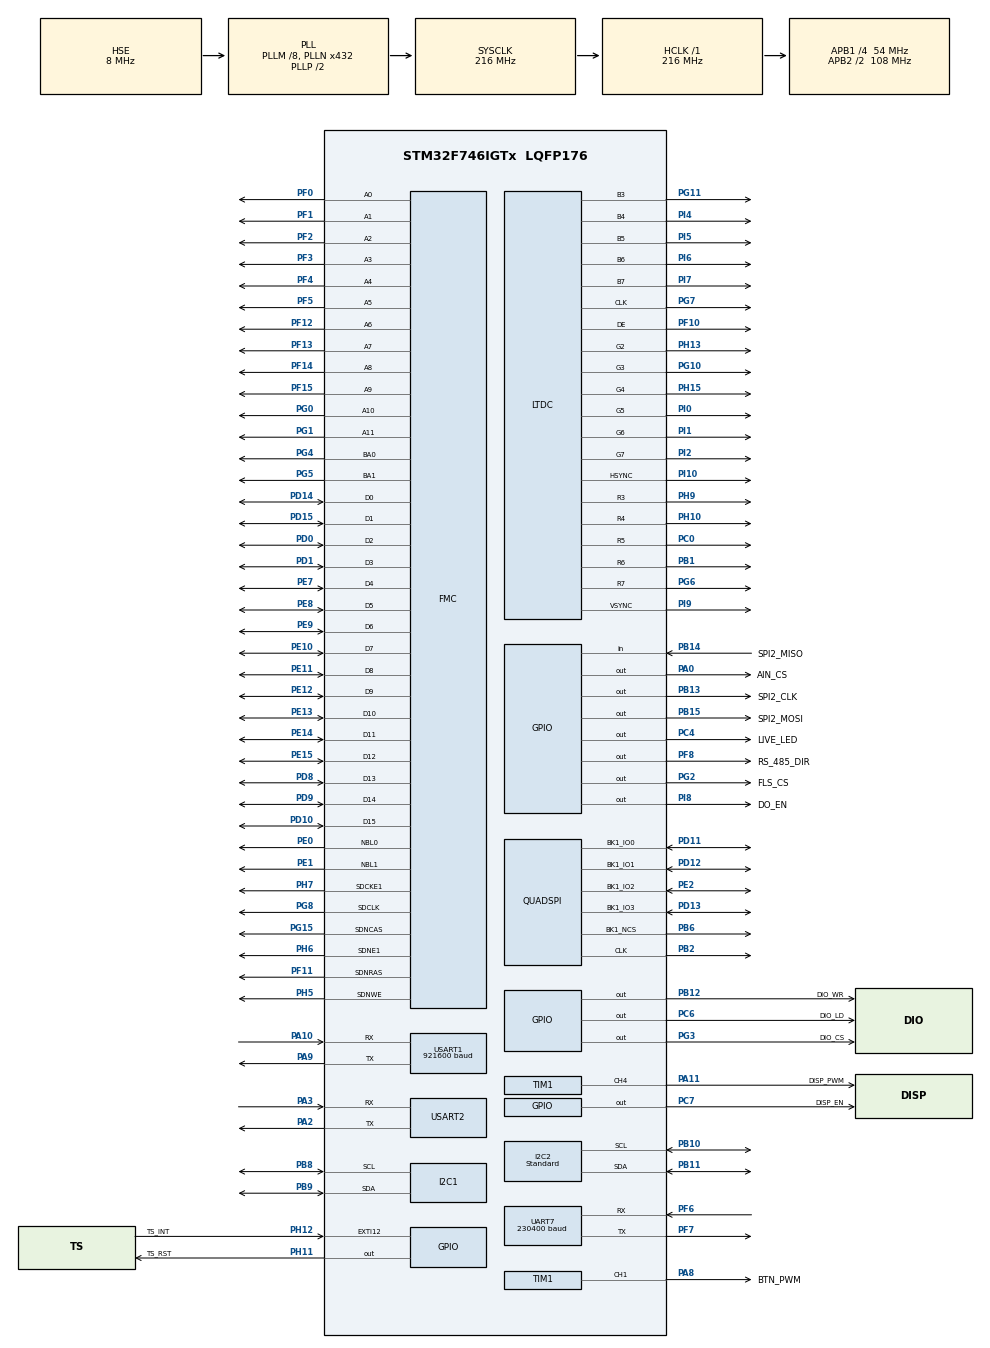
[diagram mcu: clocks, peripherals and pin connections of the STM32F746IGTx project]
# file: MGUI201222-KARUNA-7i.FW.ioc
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CORTEX_M7.ART_ACCLERATOR_ENABLE=1
CORTEX_M7.AccessPermission-Cortex_Memory_Protection_Unit_Region0_Settings=MPU_REGION_FULL_ACCESS
CORTEX_M7.AccessPermission-Cortex_Memory_Protection_Unit_Region1_Settings=MPU_REGION_FULL_ACCESS
CORTEX_M7.BaseAddress-Cortex_Memory_Protection_Unit_Region0_Settings=0x90000000
CORTEX_M7.BaseAddress-Cortex_Memory_Protection_Unit_Region1_Settings=0xD0000000
CORTEX_M7.CPU_DCache=Enabled
CORTEX_M7.CPU_ICache=Enabled
CORTEX_M7.Enable-Cortex_Memory_Protection_Unit_Region0_Settings=MPU_REGION_ENABLE
CORTEX_M7.Enable-Cortex_Memory_Protection_Unit_Region1_Settings=MPU_REGION_ENABLE
CORTEX_M7.IsCacheable-Cortex_Memory_Protection_Unit_Region0_Settings=MPU_ACCESS_NOT_CACHEABLE
CORTEX_M7.IsCacheable-Cortex_Memory_Protection_Unit_Region1_Settings=MPU_ACCESS_CACHEABLE
CORTEX_M7.MPU_Control=__NULL
CORTEX_M7.PREFETCH_ENABLE=1
CORTEX_M7.Size-Cortex_Memory_Protection_Unit_Region0_Settings=MPU_REGION_SIZE_256MB
CORTEX_M7.Size-Cortex_Memory_Protection_Unit_Region1_Settings=MPU_REGION_SIZE_256MB
CORTEX_M7.SubRegionDisable-Cortex_Memory_Protection_Unit_Region0_Settings=0x0
DMA2D.ColorMode=DMA2D_OUTPUT_RGB565
Dma.Request0=USART1_RX
Dma.Request1=UART7_RX
Dma.UART7_RX.1.Direction=DMA_PERIPH_TO_MEMORY
Dma.UART7_RX.1.FIFOMode=DMA_FIFOMODE_DISABLE
Dma.UART7_RX.1.Instance=DMA1_Stream3
Dma.UART7_RX.1.MemDataAlignment=DMA_MDATAALIGN_BYTE
Dma.UART7_RX.1.MemInc=DMA_MINC_ENABLE
Dma.UART7_RX.1.Mode=DMA_NORMAL
Dma.UART7_RX.1.PeriphDataAlignment=DMA_PDATAALIGN_BYTE
Dma.UART7_RX.1.PeriphInc=DMA_PINC_DISABLE
Dma.UART7_RX.1.Priority=DMA_PRIORITY_MEDIUM
Dma.USART1_RX.0.Direction=DMA_PERIPH_TO_MEMORY
Dma.USART1_RX.0.FIFOMode=DMA_FIFOMODE_DISABLE
Dma.USART1_RX.0.Instance=DMA2_Stream2
Dma.USART1_RX.0.MemDataAlignment=DMA_MDATAALIGN_BYTE
Dma.USART1_RX.0.MemInc=DMA_MINC_ENABLE
Dma.USART1_RX.0.Mode=DMA_NORMAL
Dma.USART1_RX.0.PeriphDataAlignment=DMA_PDATAALIGN_BYTE
Dma.USART1_RX.0.PeriphInc=DMA_PINC_DISABLE
Dma.USART1_RX.0.Priority=DMA_PRIORITY_MEDIUM
FMC.CASLatency1=FMC_SDRAM_CAS_LATENCY_3
FMC.ExitSelfRefreshDelay1=7
FMC.LoadToActiveDelay1=2
FMC.RCDDelay1=2
FMC.RPDelay1=2
FMC.RPDelay2=2
FMC.ReadBurst1=FMC_SDRAM_RBURST_ENABLE
FMC.ReadBurst2=FMC_SDRAM_RBURST_ENABLE
FMC.RowCycleDelay1=7
FMC.RowCycleDelay2=7
FMC.SDClockPeriod1=FMC_SDRAM_CLOCK_PERIOD_2
FMC.SDClockPeriod2=FMC_SDRAM_CLOCK_PERIOD_2
FMC.SelfRefreshTime1=4
FMC.WriteRecoveryTime1=3
FREERTOS.MEMORY_ALLOCATION=0
FREERTOS.Queues01=USBUartRxQueue,16,80,1,Dynamic,NULL,NULL
FREERTOS.Tasks01=defaultTask,24,8192,StartDefaultTask,Default,NULL,Dynamic,NULL,NULL;UsbRx_Task,24,8192,UsbRxTask,Default,NULL,Dynamic,NULL,NULL;LiveLed_Task,24,128,LiveLedOsTask,Default,NULL,Dynamic,NULL,NULL;RS485Rx_Task,24,8192,RS485RxTask,Default,NULL,Dynamic,NULL,NULL;RS485Tx_Task,24,128,RS485TxTask,Default,NULL,Dynamic,NULL,NULL;Peri_Task,24,128,PeriTask,Default,NULL,Dynamic,NULL,NULL
FREERTOS.configGENERATE_RUN_TIME_STATS=1
FREERTOS.configTOTAL_HEAP_SIZE=128000
FREERTOS.configUSE_APPLICATION_TASK_TAG=1
FREERTOS.configUSE_COUNTING_SEMAPHORES=1
FREERTOS.configUSE_IDLE_HOOK=1
FREERTOS.configUSE_NEWLIB_REENTRANT=1
FREERTOS.configUSE_RECURSIVE_MUTEXES=1
I2C1.Timing=0x20404768
I2C2.I2C_Speed_Mode=I2C_Standard
I2C2.Speed=40
I2C2.Timing=0x2040BEFF
LTDC.ActiveH=600
LTDC.ActiveW=1024
LTDC.Alpha_L0=0xFF
LTDC.Alpha_L1=0
LTDC.BlendingFactor1_L0=LTDC_BLENDING_FACTOR1_CA
LTDC.BlendingFactor1_L1=LTDC_BLENDING_FACTOR1_PAxCA
LTDC.BlendingFactor2_L0=LTDC_BLENDING_FACTOR2_CA
LTDC.BlendingFactor2_L1=LTDC_BLENDING_FACTOR2_PAxCA
LTDC.FBStartAdress_L0=0xD0000000
LTDC.FBStartAdress_L1=0xD0200000
LTDC.HBP=140
LTDC.HFP=160
LTDC.HSync=20
LTDC.ImageHeight_L0=600
LTDC.ImageHeight_L1=600
LTDC.ImageWidth_L0=1024
LTDC.ImageWidth_L1=1024
LTDC.Layers=0
LTDC.PixelFormat_L0=LTDC_PIXEL_FORMAT_RGB565
LTDC.VBP=20
LTDC.VFP=12
LTDC.VSync=3
LTDC.WindowX1_L0=1024
LTDC.WindowX1_L1=1024
LTDC.WindowY1_L0=600
LTDC.WindowY1_L1=600
Mcu.Family=STM32F7
Mcu.Name=STM32F746IGTx
Mcu.Package=LQFP176
NVIC.DMA1_Stream3_IRQn=true\:5\:0\:false\:false\:true\:true\:false\:true\:true
NVIC.DMA2D_IRQn=true\:5\:0\:true\:false\:true\:false\:true\:true\:true
NVIC.DMA2_Stream2_IRQn=true\:5\:0\:false\:false\:true\:true\:false\:true\:true
NVIC.EXTI15_10_IRQn=true\:5\:0\:false\:false\:true\:true\:true\:true\:true
NVIC.LTDC_ER_IRQn=true\:5\:0\:false\:false\:true\:false\:true\:true\:true
NVIC.LTDC_IRQn=true\:5\:0\:true\:false\:true\:false\:true\:true\:true
NVIC.PriorityGroup=NVIC_PRIORITYGROUP_4
NVIC.TIM6_DAC_IRQn=true\:15\:0\:false\:false\:true\:false\:false\:true\:true
NVIC.TimeBase=TIM6_DAC_IRQn
NVIC.TimeBaseIP=TIM6
PA0/WKUP.GPIO_Label=AIN_CS
PA0/WKUP.GPIO_PuPd=GPIO_PULLUP
PA0/WKUP.PinState=GPIO_PIN_SET
PA0/WKUP.Signal=GPIO_Output
PA10.Mode=Asynchronous
PA10.Signal=USART1_RX
PA11.GPIO_Label=DISP_PWM
PA11.Signal=S_TIM1_CH4
PA13.Mode=Trace_Asynchronous_SW
PA13.Signal=SYS_JTMS-SWDIO
PA14.Mode=Trace_Asynchronous_SW
PA14.Signal=SYS_JTCK-SWCLK
PA2.Mode=Asynchronous
PA2.Signal=USART2_TX
PA3.Mode=Asynchronous
PA3.Signal=USART2_RX
PA8.GPIO_Label=BTN_PWM
PA8.Signal=S_TIM1_CH1
PA9.Mode=Asynchronous
PA9.Signal=USART1_TX
PB1.GPIO_Mode=GPIO_MODE_AF_PP
PB1.GPIO_PuPd=GPIO_NOPULL
PB1.GPIO_Speed=GPIO_SPEED_FREQ_VERY_HIGH
PB1.Mode=RGB565
PB1.Signal=LTDC_R6
PB10.GPIO_Pu=GPIO_PULLUP
PB10.Mode=I2C
PB10.Signal=I2C2_SCL
PB11.GPIO_Pu=GPIO_PULLUP
PB11.Mode=I2C
PB11.Signal=I2C2_SDA
PB12.GPIO_Label=DIO_WR
PB12.Signal=GPIO_Output
PB13.GPIO_Label=SPI2_CLK
PB13.Signal=GPIO_Output
PB14.GPIO_Label=SPI2_MISO
PB14.Signal=GPIO_Input
PB15.GPIO_Label=SPI2_MOSI
PB15.Signal=GPIO_Output
PB2.Mode=Single Bank 1
PB2.Signal=QUADSPI_CLK
PB3.Mode=Trace_Asynchronous_SW
PB3.Signal=SYS_JTDO-SWO
PB6.Mode=Single Bank 1
PB6.Signal=QUADSPI_BK1_NCS
PB8.Mode=I2C
PB8.Signal=I2C1_SCL
PB9.Mode=I2C
PB9.Signal=I2C1_SDA
PC0.GPIO_Mode=GPIO_MODE_AF_PP
PC0.GPIO_PuPd=GPIO_NOPULL
PC0.GPIO_Speed=GPIO_SPEED_FREQ_VERY_HIGH
PC0.Mode=RGB565
PC0.Signal=LTDC_R5
PC14/OSC32_IN.Mode=LSE-External-Oscillator
PC14/OSC32_IN.Signal=RCC_OSC32_IN
PC15/OSC32_OUT.Mode=LSE-External-Oscillator
PC15/OSC32_OUT.Signal=RCC_OSC32_OUT
PC4.GPIO_Label=LIVE_LED
PC4.Signal=GPIO_Output
PC6.GPIO_Label=DIO_LD
PC6.Signal=GPIO_Output
PC7.GPIO_Label=DISP_EN
PC7.GPIO_PuPd=GPIO_PULLDOWN
PC7.PinState=GPIO_PIN_RESET
PC7.Signal=GPIO_Output
PD0.Signal=FMC_D2_DA2
PD1.Signal=FMC_D3_DA3
PD10.Signal=FMC_D15_DA15
PD11.Mode=Single Bank 1
PD11.Signal=QUADSPI_BK1_IO0
PD12.Mode=Single Bank 1
PD12.Signal=QUADSPI_BK1_IO1
PD13.Mode=Single Bank 1
PD13.Signal=QUADSPI_BK1_IO3
PD14.Signal=FMC_D0_DA0
PD15.Signal=FMC_D1_DA1
PD6.GPIO_Mode=GPIO_MODE_AF_PP
PD6.GPIO_PuPd=GPIO_NOPULL
PD6.GPIO_Speed=GPIO_SPEED_FREQ_VERY_HIGH
PD6.Signal=LTDC_B2
PD8.Signal=FMC_D13_DA13
PD9.Signal=FMC_D14_DA14
PE0.Signal=FMC_NBL0
PE1.Signal=FMC_NBL1
PE10.Signal=FMC_D7_DA7
PE11.Signal=FMC_D8_DA8
PE12.Signal=FMC_D9_DA9
PE13.Signal=FMC_D10_DA10
PE14.Signal=FMC_D11_DA11
PE15.Signal=FMC_D12_DA12
PE2.Mode=Single Bank 1
PE2.Signal=QUADSPI_BK1_IO2
PE4.GPIO_Mode=GPIO_MODE_AF_PP
PE4.GPIO_PuPd=GPIO_NOPULL
PE4.GPIO_Speed=GPIO_SPEED_FREQ_VERY_HIGH
PE4.Signal=LTDC_B0
PE5.GPIO_Mode=GPIO_MODE_AF_PP
PE5.GPIO_PuPd=GPIO_NOPULL
PE5.GPIO_Speed=GPIO_SPEED_FREQ_VERY_HIGH
PE5.Signal=LTDC_G0
PE6.GPIO_Mode=GPIO_MODE_AF_PP
PE6.GPIO_PuPd=GPIO_NOPULL
PE6.GPIO_Speed=GPIO_SPEED_FREQ_VERY_HIGH
PE6.Signal=LTDC_G1
PE7.Signal=FMC_D4_DA4
PE8.Signal=FMC_D5_DA5
PE9.Signal=FMC_D6_DA6
PF0.Signal=FMC_A0
PF1.Signal=FMC_A1
PF10.GPIO_Mode=GPIO_MODE_AF_PP
PF10.GPIO_PuPd=GPIO_NOPULL
PF10.GPIO_Speed=GPIO_SPEED_FREQ_VERY_HIGH
PF10.Mode=RGB565
PF10.Signal=LTDC_DE
PF11.Signal=FMC_SDNRAS
PF12.Signal=FMC_A6
PF13.Signal=FMC_A7
PF14.Signal=FMC_A8
PF15.Signal=FMC_A9
PF2.Signal=FMC_A2
PF3.Signal=FMC_A3
PF4.Signal=FMC_A4
PF5.Signal=FMC_A5
PF6.Mode=Asynchronous
PF6.Signal=UART7_RX
PF7.Mode=Asynchronous
PF7.Signal=UART7_TX
PF8.GPIO_Label=RS_485_DIR
PF8.Signal=GPIO_Output
PG0.Signal=FMC_A10
PG1.Signal=FMC_A11
PG10.GPIO_Mode=GPIO_MODE_AF_PP
PG10.GPIO_PuPd=GPIO_NOPULL
PG10.GPIO_Speed=GPIO_SPEED_FREQ_VERY_HIGH
PG10.Mode=RGB565
PG10.Signal=LTDC_G3
PG11.GPIO_Mode=GPIO_MODE_AF_PP
PG11.GPIO_PuPd=GPIO_NOPULL
PG11.GPIO_Speed=GPIO_SPEED_FREQ_VERY_HIGH
PG11.Mode=RGB565
PG11.Signal=LTDC_B3
PG12.GPIO_Mode=GPIO_MODE_AF_PP
PG12.GPIO_PuPd=GPIO_NOPULL
PG12.GPIO_Speed=GPIO_SPEED_FREQ_VERY_HIGH
PG12.Signal=LTDC_B1
PG15.Signal=FMC_SDNCAS
PG2.GPIO_Label=FLS_CS
PG2.GPIO_ModeDefaultOutputPP=GPIO_MODE_OUTPUT_PP
PG2.GPIO_PuPd=GPIO_PULLUP
PG2.GPIO_Speed=GPIO_SPEED_FREQ_LOW
PG2.PinState=GPIO_PIN_SET
PG2.Signal=GPIO_Output
PG3.GPIO_Label=DIO_CS
PG3.GPIO_ModeDefaultOutputPP=GPIO_MODE_OUTPUT_PP
PG3.GPIO_PuPd=GPIO_PULLUP
PG3.GPIO_Speed=GPIO_SPEED_FREQ_LOW
PG3.PinState=GPIO_PIN_SET
PG3.Signal=GPIO_Output
PG4.Signal=FMC_A14_BA0
PG5.Signal=FMC_A15_BA1
PG6.GPIO_Mode=GPIO_MODE_AF_PP
PG6.GPIO_PuPd=GPIO_NOPULL
PG6.GPIO_Speed=GPIO_SPEED_FREQ_VERY_HIGH
PG6.Mode=RGB565
PG6.Signal=LTDC_R7
PG7.GPIO_Mode=GPIO_MODE_AF_PP
PG7.GPIO_PuPd=GPIO_NOPULL
PG7.GPIO_Speed=GPIO_SPEED_FREQ_VERY_HIGH
PG7.Mode=RGB565
PG7.Signal=LTDC_CLK
PG8.Signal=FMC_SDCLK
PH0/OSC_IN.Mode=HSE-External-Oscillator
PH0/OSC_IN.Signal=RCC_OSC_IN
PH1/OSC_OUT.Mode=HSE-External-Oscillator
PH1/OSC_OUT.Signal=RCC_OSC_OUT
PH10.GPIO_Mode=GPIO_MODE_AF_PP
PH10.GPIO_PuPd=GPIO_NOPULL
PH10.GPIO_Speed=GPIO_SPEED_FREQ_VERY_HIGH
PH10.Mode=RGB565
PH10.Signal=LTDC_R4
PH11.GPIO_Label=TS_RST
PH11.Signal=GPIO_Output
PH12.GPIO_Label=TS_INT
PH12.GPIO_ModeDefaultEXTI=GPIO_MODE_IT_FALLING
PH12.GPIO_PuPd=GPIO_PULLUP
PH12.Signal=GPXTI12
PH13.GPIO_Mode=GPIO_MODE_AF_PP
PH13.GPIO_PuPd=GPIO_NOPULL
PH13.GPIO_Speed=GPIO_SPEED_FREQ_VERY_HIGH
PH13.Mode=RGB565
PH13.Signal=LTDC_G2
PH15.GPIO_Mode=GPIO_MODE_AF_PP
PH15.GPIO_PuPd=GPIO_NOPULL
PH15.GPIO_Speed=GPIO_SPEED_FREQ_VERY_HIGH
PH15.Mode=RGB565
PH15.Signal=LTDC_G4
PH2.GPIO_Mode=GPIO_MODE_AF_PP
PH2.GPIO_PuPd=GPIO_NOPULL
PH2.GPIO_Speed=GPIO_SPEED_FREQ_VERY_HIGH
PH2.Signal=LTDC_R0
PH3.GPIO_Mode=GPIO_MODE_AF_PP
PH3.GPIO_PuPd=GPIO_NOPULL
PH3.GPIO_Speed=GPIO_SPEED_FREQ_VERY_HIGH
PH3.Signal=LTDC_R1
PH5.Signal=FMC_SDNWE
PH6.Mode=SdramChipSelect2_1
PH6.Signal=FMC_SDNE1
PH7.Mode=SdramChipSelect2_1
PH7.Signal=FMC_SDCKE1
PH8.GPIO_Mode=GPIO_MODE_AF_PP
PH8.GPIO_PuPd=GPIO_NOPULL
PH8.GPIO_Speed=GPIO_SPEED_FREQ_VERY_HIGH
PH8.Signal=LTDC_R2
PH9.GPIO_Mode=GPIO_MODE_AF_PP
PH9.GPIO_PuPd=GPIO_NOPULL
PH9.GPIO_Speed=GPIO_SPEED_FREQ_VERY_HIGH
PH9.Mode=RGB565
PH9.Signal=LTDC_R3
PI0.GPIO_Mode=GPIO_MODE_AF_PP
PI0.GPIO_PuPd=GPIO_NOPULL
PI0.GPIO_Speed=GPIO_SPEED_FREQ_VERY_HIGH
PI0.Mode=RGB565
PI0.Signal=LTDC_G5
PI1.GPIO_Mode=GPIO_MODE_AF_PP
PI1.GPIO_PuPd=GPIO_NOPULL
PI1.GPIO_Speed=GPIO_SPEED_FREQ_VERY_HIGH
PI1.Mode=RGB565
PI1.Signal=LTDC_G6
PI10.GPIO_Mode=GPIO_MODE_AF_PP
PI10.GPIO_PuPd=GPIO_NOPULL
PI10.GPIO_Speed=GPIO_SPEED_FREQ_VERY_HIGH
PI10.Mode=RGB565
PI10.Signal=LTDC_HSYNC
PI2.GPIO_Mode=GPIO_MODE_AF_PP
PI2.GPIO_PuPd=GPIO_NOPULL
PI2.GPIO_Speed=GPIO_SPEED_FREQ_VERY_HIGH
PI2.Mode=RGB565
PI2.Signal=LTDC_G7
PI4.GPIO_Mode=GPIO_MODE_AF_PP
PI4.GPIO_PuPd=GPIO_NOPULL
PI4.GPIO_Speed=GPIO_SPEED_FREQ_VERY_HIGH
PI4.Mode=RGB565
PI4.Signal=LTDC_B4
PI5.GPIO_Mode=GPIO_MODE_AF_PP
PI5.GPIO_PuPd=GPIO_NOPULL
PI5.GPIO_Speed=GPIO_SPEED_FREQ_VERY_HIGH
PI5.Mode=RGB565
PI5.Signal=LTDC_B5
PI6.GPIO_Mode=GPIO_MODE_AF_PP
PI6.GPIO_PuPd=GPIO_NOPULL
PI6.GPIO_Speed=GPIO_SPEED_FREQ_VERY_HIGH
PI6.Mode=RGB565
PI6.Signal=LTDC_B6
PI7.GPIO_Mode=GPIO_MODE_AF_PP
PI7.GPIO_PuPd=GPIO_NOPULL
PI7.GPIO_Speed=GPIO_SPEED_FREQ_VERY_HIGH
PI7.Mode=RGB565
PI7.Signal=LTDC_B7
PI8.GPIO_Label=DO_EN
PI8.Signal=GPIO_Output
PI9.GPIO_Mode=GPIO_MODE_AF_PP
PI9.GPIO_PuPd=GPIO_NOPULL
PI9.GPIO_Speed=GPIO_SPEED_FREQ_VERY_HIGH
PI9.Mode=RGB565
PI9.Signal=LTDC_VSYNC
ProjectManager.HeapSize=0x200
ProjectManager.StackSize=0x400
ProjectManager.TargetToolchain=STM32CubeIDE
QUADSPI.ChipSelectHighTime=QSPI_CS_HIGH_TIME_6_CYCLE
QUADSPI.ClockPrescaler=5
QUADSPI.FifoThreshold=4
QUADSPI.FlashSize=25
RCC.AHBFreq_Value=216000000
RCC.APB1CLKDivider=RCC_HCLK_DIV4
RCC.APB1Freq_Value=54000000
RCC.APB1TimFreq_Value=108000000
RCC.APB2CLKDivider=RCC_HCLK_DIV2
RCC.APB2Freq_Value=108000000
RCC.APB2TimFreq_Value=216000000
RCC.CortexFreq_Value=216000000
RCC.HCLKFreq_Value=216000000
RCC.HSE_VALUE=8000000
RCC.HSI_VALUE=16000000
RCC.PLLM=8
RCC.PLLN=432
RCC.PLLSAIN=258
RCC.PLLSAIR=3
RCC.PLLSourceVirtual=RCC_PLLSOURCE_HSE
RCC.RTCClockSelection=RCC_RTCCLKSOURCE_LSE
RCC.SYSCLKFreq_VALUE=216000000
RCC.SYSCLKSource=RCC_SYSCLKSOURCE_PLLCLK
RCC.USBFreq_Value=216000000
RCC.VCOOutputFreq_Value=432000000
SH.FMC_A0.0=FMC_A0,12b-sda1
SH.FMC_A1.0=FMC_A1,12b-sda1
SH.FMC_A10.0=FMC_A10,12b-sda1
SH.FMC_A11.0=FMC_A11,12b-sda1
SH.FMC_A14_BA0.0=FMC_BA0,FourSdramBanks1
SH.FMC_A15_BA1.0=FMC_BA1,FourSdramBanks1
SH.FMC_A2.0=FMC_A2,12b-sda1
SH.FMC_A3.0=FMC_A3,12b-sda1
SH.FMC_A4.0=FMC_A4,12b-sda1
SH.FMC_A5.0=FMC_A5,12b-sda1
SH.FMC_A6.0=FMC_A6,12b-sda1
SH.FMC_A7.0=FMC_A7,12b-sda1
SH.FMC_A8.0=FMC_A8,12b-sda1
SH.FMC_A9.0=FMC_A9,12b-sda1
SH.FMC_D0_DA0.0=FMC_D0,sd-16b-d1
SH.FMC_D10_DA10.0=FMC_D10,sd-16b-d1
SH.FMC_D11_DA11.0=FMC_D11,sd-16b-d1
SH.FMC_D12_DA12.0=FMC_D12,sd-16b-d1
SH.FMC_D13_DA13.0=FMC_D13,sd-16b-d1
SH.FMC_D14_DA14.0=FMC_D14,sd-16b-d1
SH.FMC_D15_DA15.0=FMC_D15,sd-16b-d1
SH.FMC_D1_DA1.0=FMC_D1,sd-16b-d1
SH.FMC_D2_DA2.0=FMC_D2,sd-16b-d1
SH.FMC_D3_DA3.0=FMC_D3,sd-16b-d1
SH.FMC_D4_DA4.0=FMC_D4,sd-16b-d1
SH.FMC_D5_DA5.0=FMC_D5,sd-16b-d1
SH.FMC_D6_DA6.0=FMC_D6,sd-16b-d1
SH.FMC_D7_DA7.0=FMC_D7,sd-16b-d1
SH.FMC_D8_DA8.0=FMC_D8,sd-16b-d1
SH.FMC_D9_DA9.0=FMC_D9,sd-16b-d1
SH.FMC_NBL0.0=FMC_NBL0,Sd2ByteEnable1
SH.FMC_NBL1.0=FMC_NBL1,Sd2ByteEnable1
SH.FMC_SDCLK.0=FMC_SDCLK,12b-sda1
SH.FMC_SDNCAS.0=FMC_SDNCAS,12b-sda1
SH.FMC_SDNRAS.0=FMC_SDNRAS,12b-sda1
SH.FMC_SDNWE.0=FMC_SDNWE,12b-sda1
SH.S_TIM1_CH1.0=TIM1_CH1,PWM Generation1 CH1
SH.S_TIM1_CH4.0=TIM1_CH4,PWM Generation4 CH4
STMicroelectronics.X-CUBE-TOUCHGFX.4.19.1.ApplicationCcGraphicsJjApplication=TouchGFXOoGenerator
STMicroelectronics.X-CUBE-TOUCHGFX.4.19.1.tgfx_address1=0xD0000000
STMicroelectronics.X-CUBE-TOUCHGFX.4.19.1.tgfx_address2=0xD0000000
STMicroelectronics.X-CUBE-TOUCHGFX.4.19.1.tgfx_display_interface=disp_ltdc
STMicroelectronics.X-CUBE-TOUCHGFX.4.19.1.tgfx_hardware_accelerator=dma_2d
STMicroelectronics.X-CUBE-TOUCHGFX.4.19.1.tgfx_location=By Address
STMicroelectronics.X-CUBE-TOUCHGFX.4.19.1.tgfx_vsync=vsync_ltdc
TIM1.Channel-PWM\ Generation1\ CH1=TIM_CHANNEL_1
TIM1.Channel-PWM\ Generation4\ CH4=TIM_CHANNEL_4
TIM1.Period=10000
TIM1.Pulse-PWM\ Generation1\ CH1=5000
TIM1.Pulse-PWM\ Generation4\ CH4=5000
UART7.BaudRate=230400
UART7.DMADisableonRxErrorParam=UART_ADVFEATURE_DMA_ENABLEONRXERROR
UART7.TxPinLevelInvertParam=UART_ADVFEATURE_TXINV_DISABLE
USART1.BaudRate=921600
USART1.VirtualMode-Asynchronous=VM_ASYNC
USART2.VirtualMode-Asynchronous=VM_ASYNC
VP_CRC_VS_CRC.Mode=CRC_Activate
VP_DMA2D_VS_DMA2D.Mode=DMA2D_Activate
VP_FREERTOS_VS_CMSIS_V2.Mode=CMSIS_V2
VP_RTC_VS_RTC_Activate.Mode=RTC_Enabled
VP_STMicroelectronics.X-CUBE-TOUCHGFX_VS_GraphicsJjApplication_4.19.1.Mode=GraphicsJjApplication
VP_SYS_VS_tim6.Mode=TIM6
VP_TIM1_VS_ClockSourceINT.Mode=Internal
VP_TIM2_VS_ClockSourceINT.Mode=Internal
board=STM32F746I

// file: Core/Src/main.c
/* USER CODE BEGIN Header */
/**
  ******************************************************************************
  * @file           : main.c
  * @brief          : Main program body
  ******************************************************************************
  * @attention
  *
  * <h2><center>&copy; Copyright (c) 2020 STMicroelectronics.
  * All rights reserved.</center></h2>
  *
  * This software component is licensed by ST under Ultimate Liberty license
  * SLA0044, the "License"; You may not use this file except in compliance with
  * the License. You may obtain a copy of the License at:
  *                             www.st.com/SLA0044
  *
  ******************************************************************************
  */
/* USER CODE END Header */
#include "main.h"
#include "cmsis_os.h"
#include "app_touchgfx.h"

/* USER CODE BEGIN Includes */
#include "string.h"
#include "mx25.h"
#include <stdio.h>
#include <queue.h>
#include <stdlib.h>
#include "GuiItf.h"
#include <time.h>
#include "Log.h"

/* USER CODE END Includes */

/* USER CODE BEGIN PTD */

typedef enum RS485ItemType
{
  TX_ITEM_NO_ARG,
  TX_ITEM_INT_ARG
}RS485ItemType_t;

typedef struct _RS485TxItem
{
  char Command[RS485_CMD_LENGTH];
  uint8_t HostAddr;
  RS485ItemType_t Type;
  void (*Arg1);
  uint32_t PeriodTime;
  int32_t Timesamp;
}RS485TxItem_t;

/* USER CODE END PTD */

/* USER CODE BEGIN PD */

/*** SDRAM ***/
/* SDRAM refresh counter (100Mhz SD clock)    */
#define SDRAM_REFRESH_COUNT                      ((uint32_t)0x0603)
#define SDRAM_TIMEOUT                            ((uint32_t)0xFFFF)
#define SDRAM_DEVICE_ADDR                        ((uint32_t)0xD0000000)
/* SDRAM device size in MBytes */
#define SDRAM_DEVICE_SIZE                        ((uint32_t)0x800000)
#define SDRAM_MODEREG_BURST_LENGTH_1             ((uint16_t)0x0000)
#define SDRAM_MODEREG_BURST_LENGTH_2             ((uint16_t)0x0001)
#define SDRAM_MODEREG_BURST_LENGTH_4             ((uint16_t)0x0002)
#define SDRAM_MODEREG_BURST_LENGTH_8             ((uint16_t)0x0004)
#define SDRAM_MODEREG_BURST_TYPE_SEQUENTIAL      ((uint16_t)0x0000)
#define SDRAM_MODEREG_BURST_TYPE_INTERLEAVED     ((uint16_t)0x0008)
#define SDRAM_MODEREG_CAS_LATENCY_2              ((uint16_t)0x0020)
#define SDRAM_MODEREG_CAS_LATENCY_3              ((uint16_t)0x0030)
#define SDRAM_MODEREG_OPERATING_MODE_STANDARD    ((uint16_t)0x0000)
#define SDRAM_MODEREG_WRITEBURST_MODE_PROGRAMMED ((uint16_t)0x0000)
#define SDRAM_MODEREG_WRITEBURST_MODE_SINGLE     ((uint16_t)0x0200)
#define SDRAM_BUFFER_SIZE                        ((uint32_t)0x1000)

/* USER CODE END PD */

CRC_HandleTypeDef hcrc;

DMA2D_HandleTypeDef hdma2d;

I2C_HandleTypeDef hi2c1;
I2C_HandleTypeDef hi2c2;

LTDC_HandleTypeDef hltdc;

QSPI_HandleTypeDef hqspi;

RTC_HandleTypeDef hrtc;

TIM_HandleTypeDef htim1;
TIM_HandleTypeDef htim2;

UART_HandleTypeDef huart7;
UART_HandleTypeDef huart1;
UART_HandleTypeDef huart2;
DMA_HandleTypeDef hdma_uart7_rx;
DMA_HandleTypeDef hdma_usart1_rx;

SDRAM_HandleTypeDef hsdram1;

/* Definitions for defaultTask */
osThreadId_t defaultTaskHandle;
const osThreadAttr_t defaultTask_attributes = {
  .name = "defaultTask",
  .stack_size = 8192 * 4,
  .priority = (osPriority_t) osPriorityNormal,
};
/* Definitions for UsbRx_Task */
osThreadId_t UsbRx_TaskHandle;
const osThreadAttr_t UsbRx_Task_attributes = {
  .name = "UsbRx_Task",
  .stack_size = 8192 * 4,
  .priority = (osPriority_t) osPriorityNormal,
};
/* Definitions for LiveLed_Task */
osThreadId_t LiveLed_TaskHandle;
const osThreadAttr_t LiveLed_Task_attributes = {
  .name = "LiveLed_Task",
  .stack_size = 128 * 4,
  .priority = (osPriority_t) osPriorityNormal,
};
/* Definitions for RS485Rx_Task */
osThreadId_t RS485Rx_TaskHandle;
const osThreadAttr_t RS485Rx_Task_attributes = {
  .name = "RS485Rx_Task",
  .stack_size = 8192 * 4,
  .priority = (osPriority_t) osPriorityNormal,
};
/* Definitions for RS485Tx_Task */
osThreadId_t RS485Tx_TaskHandle;
const osThreadAttr_t RS485Tx_Task_attributes = {
  .name = "RS485Tx_Task",
  .stack_size = 128 * 4,
  .priority = (osPriority_t) osPriorityNormal,
};
/* Definitions for Peri_Task */
osThreadId_t Peri_TaskHandle;
const osThreadAttr_t Peri_Task_attributes = {
  .name = "Peri_Task",
  .stack_size = 128 * 4,
  .priority = (osPriority_t) osPriorityNormal,
};
/* Definitions for USBUartRxQueue */
osMessageQueueId_t USBUartRxQueueHandle;
const osMessageQueueAttr_t USBUartRxQueue_attributes = {
  .name = "USBUartRxQueue"
};
/* USER CODE BEGIN PV */
#define husb      huart1
#define hRs485    huart7

Device_t Device;
__IO unsigned long RTOSRunTimeStatTick;

static char USB_UART_RxBuffer[USB_BUFFER_SIZE];
static char RS485_UART_RxBuffer[RS485_BUFFER_SIZE];

RS485TxItem_t RS485TxCollection[] =
{
  /*** Karuna ***/
  {"#%02X UPTIME?", KRN_HOST_TX_ADDR, TX_ITEM_NO_ARG, NULL, 200,},
  {"#%02X DI?",     KRN_HOST_TX_ADDR, TX_ITEM_NO_ARG, NULL, 100 },
  {"#%02X DO %08X", KRN_HOST_TX_ADDR, TX_ITEM_INT_ARG, &Device.Karuna.DO, 100 },
  {"#%02X FW?",     KRN_HOST_TX_ADDR, TX_ITEM_NO_ARG, NULL, 4000 },
  {"#%02X UID?",    KRN_HOST_TX_ADDR, TX_ITEM_NO_ARG, NULL, 4200 },
  {"#%02X PCB?",    KRN_HOST_TX_ADDR, TX_ITEM_NO_ARG, NULL, 4600 },
  {"#%02X UE?",     KRN_HOST_TX_ADDR, TX_ITEM_NO_ARG, NULL, 4800 },

#ifdef KARUNA_7i
  /*** DasClock ***/
  {"#%02X UPTIME?", DAS_HOST_TX_ADDR, TX_ITEM_NO_ARG, NULL, 200,},
  {"#%02X FW?",     DAS_HOST_TX_ADDR, TX_ITEM_NO_ARG, NULL, 5000 },
  {"#%02X UID?",    DAS_HOST_TX_ADDR, TX_ITEM_NO_ARG, NULL, 5200 },
  {"#%02X PCB?",    DAS_HOST_TX_ADDR, TX_ITEM_NO_ARG, NULL, 5400 },
  {"#%02X UE?",     DAS_HOST_TX_ADDR, TX_ITEM_NO_ARG, NULL, 5400 },

  {"#%02X DI?",     DAS_HOST_TX_ADDR, TX_ITEM_NO_ARG, NULL, 200 },
  {"#%02X AI? 0",   DAS_HOST_TX_ADDR, TX_ITEM_NO_ARG, NULL ,2100 },
  {"#%02X AI? 1",   DAS_HOST_TX_ADDR, TX_ITEM_NO_ARG, NULL ,2200 },
  {"#%02X AI? 2",   DAS_HOST_TX_ADDR, TX_ITEM_NO_ARG, NULL ,2300 },
  {"#%02X AI? 3",   DAS_HOST_TX_ADDR, TX_ITEM_NO_ARG, NULL ,2400 },
  {"#%02X AI? 4",   DAS_HOST_TX_ADDR, TX_ITEM_NO_ARG, NULL ,2500 },
  {"#%02X AI? 5",   DAS_HOST_TX_ADDR, TX_ITEM_NO_ARG, NULL ,2600 },
  {"#%02X AI? 6",   DAS_HOST_TX_ADDR, TX_ITEM_NO_ARG, NULL ,2700 },
#endif
};

/* USER CODE END PV */

void SystemClock_Config(void);
static void MX_GPIO_Init(void);
static void MX_DMA2D_Init(void);
static void MX_FMC_Init(void);
static void MX_DMA_Init(void);
static void MX_LTDC_Init(void);
static void MX_CRC_Init(void);
static void MX_I2C2_Init(void);
static void MX_QUADSPI_Init(void);
static void MX_TIM1_Init(void);
static void MX_USART2_UART_Init(void);
static void MX_USART1_UART_Init(void);
static void MX_UART7_Init(void);
static void MX_TIM2_Init(void);
static void MX_I2C1_Init(void);
static void MX_RTC_Init(void);
void StartDefaultTask(void *argument);
void UsbRxTask(void *argument);
void LiveLedOsTask(void *argument);
void RS485RxTask(void *argument);
void RS485TxTask(void *argument);
void PeriTask(void *argument);

/* USER CODE BEGIN PFP */
/*** Live LED***/
void LiveLedOff(void);
void LiveLedOn(void);

/*** LCD ***/
void ConsoleWrite(char *str);
void UsbParser(char *request);
void UsbUartTx(char *str);

/*** RS485 ***/
void RS485DirTx(void);
void RS485DirRx(void);
void RS485Parser(char *response);
void RS485UartTx(char *str);

uint8_t DeviceTimeUpdate(void);

/* USER CODE END PFP */

int main(void)
{

  /* Enable I-Cache---------------------------------------------------------*/
  SCB_EnableICache();

  /* Enable D-Cache---------------------------------------------------------*/
  SCB_EnableDCache();

  /* MCU Configuration--------------------------------------------------------*/

  /* Reset of all peripherals, Initializes the Flash interface and the Systick. */
  HAL_Init();

  /* Configure the system clock */
  SystemClock_Config();

  /* Initialize all configured peripherals */
  MX_GPIO_Init();
  MX_DMA2D_Init();
  MX_FMC_Init();
  MX_DMA_Init();
  MX_LTDC_Init();
  MX_CRC_Init();
  MX_I2C2_Init();
  MX_QUADSPI_Init();
  MX_TIM1_Init();
  MX_USART2_UART_Init();
  MX_USART1_UART_Init();
  MX_UART7_Init();
  MX_TIM2_Init();
  MX_I2C1_Init();
  MX_RTC_Init();
  MX_TouchGFX_Init();
  /* USER CODE BEGIN 2 */

  /*** Display ***/
  BacklightEn(0);

  /*** Flash ***/
  MX25_Init(&hqspi);
  MX25_EnableMemoryMappedMode(&hqspi);
  HAL_NVIC_DisableIRQ(QUADSPI_IRQn);

  /*** Leds ***/
  BacklightInit(&htim1);
  BacklightSet(100);

  PowerLedInit(&htim1);
  PowerSetLedLight(10);
  PowerLedSetState(PWR_LED_ON);

  /*** EEPROM ***/
  EepromInit(&hi2c1);
  GuiItfLoad();

  /*** Versions ***/
  sprintf(Device.Gui.FW, "%s",DEVICE_FW);
  sprintf(Device.Gui.UID, "%4lX%4lX%4lX",HAL_GetUIDw0(), HAL_GetUIDw1(), HAL_GetUIDw2());
  sprintf(Device.Gui.PCB, "%s",DEVICE_PCB);

  /*** Date ***/
  DeviceTimeUpdate();

  /*** Falsh Playgorund ***/
#ifdef OFF_LOG_UPLOAD
  char buf[256];
  for(uint32_t i = 0; i < GuiItfLogGetLastAddress(); i++)
  {
    GuitItfLogGetLine(i,buf, sizeof(buf));
    printf( "%s\n", buf);
  }
#endif

  /*** Time Zone ***/
  setenv("TZ", "UTC", 0);
  tzset();

  /* USER CODE END 2 */

  /* Init scheduler */
  osKernelInitialize();

  /* Create the queue(s) */
  /* creation of USBUartRxQueue */
  USBUartRxQueueHandle = osMessageQueueNew (16, 80, &USBUartRxQueue_attributes);

  /* Create the thread(s) */
  /* creation of defaultTask */
  defaultTaskHandle = osThreadNew(StartDefaultTask, NULL, &defaultTask_attributes);

  /* creation of UsbRx_Task */
  UsbRx_TaskHandle = osThreadNew(UsbRxTask, NULL, &UsbRx_Task_attributes);

  /* creation of LiveLed_Task */
  LiveLed_TaskHandle = osThreadNew(LiveLedOsTask, NULL, &LiveLed_Task_attributes);

  /* creation of RS485Rx_Task */
  RS485Rx_TaskHandle = osThreadNew(RS485RxTask, NULL, &RS485Rx_Task_attributes);

  /* creation of RS485Tx_Task */
  RS485Tx_TaskHandle = osThreadNew(RS485TxTask, NULL, &RS485Tx_Task_attributes);

  /* creation of Peri_Task */
  Peri_TaskHandle = osThreadNew(PeriTask, NULL, &Peri_Task_attributes);

  /* Start scheduler */
  osKernelStart();

  /* We should never get here as control is now taken by the scheduler */
  /* Infinite loop */
  while (1)
  {

  }
}

void SystemClock_Config(void)
{
  RCC_OscInitTypeDef RCC_OscInitStruct = {0};
  RCC_ClkInitTypeDef RCC_ClkInitStruct = {0};

  /** Configure LSE Drive Capability
  */
  HAL_PWR_EnableBkUpAccess();
  __HAL_RCC_LSEDRIVE_CONFIG(RCC_LSEDRIVE_LOW);

  /** Configure the main internal regulator output voltage
  */
  __HAL_RCC_PWR_CLK_ENABLE();
  __HAL_PWR_VOLTAGESCALING_CONFIG(PWR_REGULATOR_VOLTAGE_SCALE1);

  /** Initializes the RCC Oscillators according to the specified parameters
  * in the RCC_OscInitTypeDef structure.
  */
  RCC_OscInitStruct.OscillatorType = RCC_OSCILLATORTYPE_HSE|RCC_OSCILLATORTYPE_LSE;
  RCC_OscInitStruct.HSEState = RCC_HSE_ON;
  RCC_OscInitStruct.LSEState = RCC_LSE_ON;
  RCC_OscInitStruct.PLL.PLLState = RCC_PLL_ON;
  RCC_OscInitStruct.PLL.PLLSource = RCC_PLLSOURCE_HSE;
  RCC_OscInitStruct.PLL.PLLM = 8;
  RCC_OscInitStruct.PLL.PLLN = 432;
  RCC_OscInitStruct.PLL.PLLP = RCC_PLLP_DIV2;
  RCC_OscInitStruct.PLL.PLLQ = 2;
  if (HAL_RCC_OscConfig(&RCC_OscInitStruct) != HAL_OK)
  {
    Error_Handler();
  }

  /** Activate the Over-Drive mode
  */
  if (HAL_PWREx_EnableOverDrive() != HAL_OK)
  {
    Error_Handler();
  }

  /** Initializes the CPU, AHB and APB buses clocks
  */
  RCC_ClkInitStruct.ClockType = RCC_CLOCKTYPE_HCLK|RCC_CLOCKTYPE_SYSCLK
                              |RCC_CLOCKTYPE_PCLK1|RCC_CLOCKTYPE_PCLK2;
  RCC_ClkInitStruct.SYSCLKSource = RCC_SYSCLKSOURCE_PLLCLK;
  RCC_ClkInitStruct.AHBCLKDivider = RCC_SYSCLK_DIV1;
  RCC_ClkInitStruct.APB1CLKDivider = RCC_HCLK_DIV4;
  RCC_ClkInitStruct.APB2CLKDivider = RCC_HCLK_DIV2;

  if (HAL_RCC_ClockConfig(&RCC_ClkInitStruct, FLASH_LATENCY_7) != HAL_OK)
  {
    Error_Handler();
  }
}

static void MX_CRC_Init(void)
{

  hcrc.Instance = CRC;
  hcrc.Init.DefaultPolynomialUse = DEFAULT_POLYNOMIAL_ENABLE;
  hcrc.Init.DefaultInitValueUse = DEFAULT_INIT_VALUE_ENABLE;
  hcrc.Init.InputDataInversionMode = CRC_INPUTDATA_INVERSION_NONE;
  hcrc.Init.OutputDataInversionMode = CRC_OUTPUTDATA_INVERSION_DISABLE;
  hcrc.InputDataFormat = CRC_INPUTDATA_FORMAT_BYTES;
  if (HAL_CRC_Init(&hcrc) != HAL_OK)
  {
    Error_Handler();
  }

}

static void MX_DMA2D_Init(void)
{

  hdma2d.Instance = DMA2D;
  hdma2d.Init.Mode = DMA2D_M2M;
  hdma2d.Init.ColorMode = DMA2D_OUTPUT_RGB565;
  hdma2d.Init.OutputOffset = 0;
  hdma2d.LayerCfg[1].InputOffset = 0;
  hdma2d.LayerCfg[1].InputColorMode = DMA2D_INPUT_RGB565;
  hdma2d.LayerCfg[1].AlphaMode = DMA2D_NO_MODIF_ALPHA;
  hdma2d.LayerCfg[1].InputAlpha = 0;
  if (HAL_DMA2D_Init(&hdma2d) != HAL_OK)
  {
    Error_Handler();
  }
  if (HAL_DMA2D_ConfigLayer(&hdma2d, 1) != HAL_OK)
  {
    Error_Handler();
  }

}

static void MX_I2C1_Init(void)
{

  hi2c1.Instance = I2C1;
  hi2c1.Init.Timing = 0x20404768;
  hi2c1.Init.OwnAddress1 = 0;
  hi2c1.Init.AddressingMode = I2C_ADDRESSINGMODE_7BIT;
  hi2c1.Init.DualAddressMode = I2C_DUALADDRESS_DISABLE;
  hi2c1.Init.OwnAddress2 = 0;
  hi2c1.Init.OwnAddress2Masks = I2C_OA2_NOMASK;
  hi2c1.Init.GeneralCallMode = I2C_GENERALCALL_DISABLE;
  hi2c1.Init.NoStretchMode = I2C_NOSTRETCH_DISABLE;
  if (HAL_I2C_Init(&hi2c1) != HAL_OK)
  {
    Error_Handler();
  }

  /** Configure Analogue filter
  */
  if (HAL_I2CEx_ConfigAnalogFilter(&hi2c1, I2C_ANALOGFILTER_ENABLE) != HAL_OK)
  {
    Error_Handler();
  }

  /** Configure Digital filter
  */
  if (HAL_I2CEx_ConfigDigitalFilter(&hi2c1, 0) != HAL_OK)
  {
    Error_Handler();
  }

}

static void MX_I2C2_Init(void)
{

  hi2c2.Instance = I2C2;
  hi2c2.Init.Timing = 0x2040BEFF;
  hi2c2.Init.OwnAddress1 = 0;
  hi2c2.Init.AddressingMode = I2C_ADDRESSINGMODE_7BIT;
  hi2c2.Init.DualAddressMode = I2C_DUALADDRESS_DISABLE;
  hi2c2.Init.OwnAddress2 = 0;
  hi2c2.Init.OwnAddress2Masks = I2C_OA2_NOMASK;
  hi2c2.Init.GeneralCallMode = I2C_GENERALCALL_DISABLE;
  hi2c2.Init.NoStretchMode = I2C_NOSTRETCH_DISABLE;
  if (HAL_I2C_Init(&hi2c2) != HAL_OK)
  {
    Error_Handler();
  }

  /** Configure Analogue filter
  */
  if (HAL_I2CEx_ConfigAnalogFilter(&hi2c2, I2C_ANALOGFILTER_ENABLE) != HAL_OK)
  {
    Error_Handler();
  }

  /** Configure Digital filter
  */
  if (HAL_I2CEx_ConfigDigitalFilter(&hi2c2, 0) != HAL_OK)
  {
    Error_Handler();
  }

}

static void MX_LTDC_Init(void)
{

  LTDC_LayerCfgTypeDef pLayerCfg = {0};

  /* USER CODE BEGIN LTDC_Init 1 */
#ifdef KARUNA_7i
  /* USER CODE END LTDC_Init 1 */
  hltdc.Instance = LTDC;
  hltdc.Init.HSPolarity = LTDC_HSPOLARITY_AL;
  hltdc.Init.VSPolarity = LTDC_VSPOLARITY_AL;
  hltdc.Init.DEPolarity = LTDC_DEPOLARITY_AL;
  hltdc.Init.PCPolarity = LTDC_PCPOLARITY_IPC;
  hltdc.Init.HorizontalSync = 19;
  hltdc.Init.VerticalSync = 2;
  hltdc.Init.AccumulatedHBP = 159;
  hltdc.Init.AccumulatedVBP = 22;
  hltdc.Init.AccumulatedActiveW = 1183;
  hltdc.Init.AccumulatedActiveH = 622;
  hltdc.Init.TotalWidth = 1343;
  hltdc.Init.TotalHeigh = 634;
  hltdc.Init.Backcolor.Blue = 0;
  hltdc.Init.Backcolor.Green = 0;
  hltdc.Init.Backcolor.Red = 0;
  if (HAL_LTDC_Init(&hltdc) != HAL_OK)
  {
    Error_Handler();
  }
  pLayerCfg.WindowX0 = 0;
  pLayerCfg.WindowX1 = 1024;
  pLayerCfg.WindowY0 = 0;
  pLayerCfg.WindowY1 = 600;
  pLayerCfg.PixelFormat = LTDC_PIXEL_FORMAT_RGB565;
  pLayerCfg.Alpha = 0xFF;
  pLayerCfg.Alpha0 = 0;
  pLayerCfg.BlendingFactor1 = LTDC_BLENDING_FACTOR1_CA;
  pLayerCfg.BlendingFactor2 = LTDC_BLENDING_FACTOR2_CA;
  pLayerCfg.FBStartAdress = 0xD0000000;
  pLayerCfg.ImageWidth = 1024;
  pLayerCfg.ImageHeight = 600;
  pLayerCfg.Backcolor.Blue = 0;
  pLayerCfg.Backcolor.Green = 0;
  pLayerCfg.Backcolor.Red = 0;
  if (HAL_LTDC_ConfigLayer(&hltdc, &pLayerCfg, 0) != HAL_OK)
  {
    Error_Handler();
  }
  /* USER CODE BEGIN LTDC_Init 2 */
#endif

#ifdef KARUNA_43i
  hltdc.Instance = LTDC;
  hltdc.Init.HSPolarity = LTDC_HSPOLARITY_AL;
  hltdc.Init.VSPolarity = LTDC_VSPOLARITY_AL;
  hltdc.Init.DEPolarity = LTDC_DEPOLARITY_AL;
  hltdc.Init.PCPolarity = LTDC_PCPOLARITY_IPC;
  hltdc.Init.HorizontalSync = 19;
  hltdc.Init.VerticalSync = 2;
  hltdc.Init.AccumulatedHBP = 159;
  hltdc.Init.AccumulatedVBP = 22;
  hltdc.Init.AccumulatedActiveW = 959;
  hltdc.Init.AccumulatedActiveH = 502;
  hltdc.Init.TotalWidth = 1119;
  hltdc.Init.TotalHeigh = 514;
  hltdc.Init.Backcolor.Blue = 0;
  hltdc.Init.Backcolor.Green = 0;
  hltdc.Init.Backcolor.Red = 0;
  if (HAL_LTDC_Init(&hltdc) != HAL_OK)
  {
    Error_Handler();
  }
  pLayerCfg.WindowX0 = 0;
  pLayerCfg.WindowX1 = 800;
  pLayerCfg.WindowY0 = 0;
  pLayerCfg.WindowY1 = 480;
  pLayerCfg.PixelFormat = LTDC_PIXEL_FORMAT_RGB565;
  pLayerCfg.Alpha = 0xFF;
  pLayerCfg.Alpha0 = 0;
  pLayerCfg.BlendingFactor1 = LTDC_BLENDING_FACTOR1_CA;
  pLayerCfg.BlendingFactor2 = LTDC_BLENDING_FACTOR2_CA;
  pLayerCfg.FBStartAdress = 0xD0000000;
  pLayerCfg.ImageWidth = 800;
  pLayerCfg.ImageHeight = 480;
  pLayerCfg.Backcolor.Blue = 0;
  pLayerCfg.Backcolor.Green = 0;
  pLayerCfg.Backcolor.Red = 0;
  if (HAL_LTDC_ConfigLayer(&hltdc, &pLayerCfg, 0) != HAL_OK)
  {
    Error_Handler();
  }
#endif

  /* USER CODE END LTDC_Init 2 */

}

static void MX_QUADSPI_Init(void)
{

  /* QUADSPI parameter configuration*/
  hqspi.Instance = QUADSPI;
  hqspi.Init.ClockPrescaler = 5;
  hqspi.Init.FifoThreshold = 4;
  hqspi.Init.SampleShifting = QSPI_SAMPLE_SHIFTING_NONE;
  hqspi.Init.FlashSize = 25;
  hqspi.Init.ChipSelectHighTime = QSPI_CS_HIGH_TIME_6_CYCLE;
  hqspi.Init.ClockMode = QSPI_CLOCK_MODE_0;
  hqspi.Init.FlashID = QSPI_FLASH_ID_1;
  hqspi.Init.DualFlash = QSPI_DUALFLASH_DISABLE;
  if (HAL_QSPI_Init(&hqspi) != HAL_OK)
  {
    Error_Handler();
  }

}

static void MX_RTC_Init(void)
{

  /** Initialize RTC Only
  */
  hrtc.Instance = RTC;
  hrtc.Init.HourFormat = RTC_HOURFORMAT_24;
  hrtc.Init.AsynchPrediv = 127;
  hrtc.Init.SynchPrediv = 255;
  hrtc.Init.OutPut = RTC_OUTPUT_DISABLE;
  hrtc.Init.OutPutPolarity = RTC_OUTPUT_POLARITY_HIGH;
  hrtc.Init.OutPutType = RTC_OUTPUT_TYPE_OPENDRAIN;
  if (HAL_RTC_Init(&hrtc) != HAL_OK)
  {
    Error_Handler();
  }

}

static void MX_TIM1_Init(void)
{

  TIM_ClockConfigTypeDef sClockSourceConfig = {0};
  TIM_MasterConfigTypeDef sMasterConfig = {0};
  TIM_OC_InitTypeDef sConfigOC = {0};
  TIM_BreakDeadTimeConfigTypeDef sBreakDeadTimeConfig = {0};

  htim1.Instance = TIM1;
  htim1.Init.Prescaler = 0;
  htim1.Init.CounterMode = TIM_COUNTERMODE_UP;
  htim1.Init.Period = 10000;
  htim1.Init.ClockDivision = TIM_CLOCKDIVISION_DIV1;
  htim1.Init.RepetitionCounter = 0;
  htim1.Init.AutoReloadPreload = TIM_AUTORELOAD_PRELOAD_DISABLE;
  if (HAL_TIM_Base_Init(&htim1) != HAL_OK)
  {
    Error_Handler();
  }
  sClockSourceConfig.ClockSource = TIM_CLOCKSOURCE_INTERNAL;
  if (HAL_TIM_ConfigClockSource(&htim1, &sClockSourceConfig) != HAL_OK)
  {
    Error_Handler();
  }
  if (HAL_TIM_PWM_Init(&htim1) != HAL_OK)
  {
    Error_Handler();
  }
  sMasterConfig.MasterOutputTrigger = TIM_TRGO_RESET;
  sMasterConfig.MasterOutputTrigger2 = TIM_TRGO2_RESET;
  sMasterConfig.MasterSlaveMode = TIM_MASTERSLAVEMODE_DISABLE;
  if (HAL_TIMEx_MasterConfigSynchronization(&htim1, &sMasterConfig) != HAL_OK)
  {
    Error_Handler();
  }
  sConfigOC.OCMode = TIM_OCMODE_PWM1;
  sConfigOC.Pulse = 5000;
  sConfigOC.OCPolarity = TIM_OCPOLARITY_HIGH;
  sConfigOC.OCNPolarity = TIM_OCNPOLARITY_HIGH;
  sConfigOC.OCFastMode = TIM_OCFAST_DISABLE;
  sConfigOC.OCIdleState = TIM_OCIDLESTATE_RESET;
  sConfigOC.OCNIdleState = TIM_OCNIDLESTATE_RESET;
  if (HAL_TIM_PWM_ConfigChannel(&htim1, &sConfigOC, TIM_CHANNEL_1) != HAL_OK)
  {
    Error_Handler();
  }
  if (HAL_TIM_PWM_ConfigChannel(&htim1, &sConfigOC, TIM_CHANNEL_4) != HAL_OK)
  {
    Error_Handler();
  }
  sBreakDeadTimeConfig.OffStateRunMode = TIM_OSSR_DISABLE;
  sBreakDeadTimeConfig.OffStateIDLEMode = TIM_OSSI_DISABLE;
  sBreakDeadTimeConfig.LockLevel = TIM_LOCKLEVEL_OFF;
  sBreakDeadTimeConfig.DeadTime = 0;
  sBreakDeadTimeConfig.BreakState = TIM_BREAK_DISABLE;
  sBreakDeadTimeConfig.BreakPolarity = TIM_BREAKPOLARITY_HIGH;
  sBreakDeadTimeConfig.BreakFilter = 0;
  sBreakDeadTimeConfig.Break2State = TIM_BREAK2_DISABLE;
  sBreakDeadTimeConfig.Break2Polarity = TIM_BREAK2POLARITY_HIGH;
  sBreakDeadTimeConfig.Break2Filter = 0;
  sBreakDeadTimeConfig.AutomaticOutput = TIM_AUTOMATICOUTPUT_DISABLE;
  if (HAL_TIMEx_ConfigBreakDeadTime(&htim1, &sBreakDeadTimeConfig) != HAL_OK)
  {
    Error_Handler();
  }
  HAL_TIM_MspPostInit(&htim1);

}

static void MX_TIM2_Init(void)
{

  TIM_ClockConfigTypeDef sClockSourceConfig = {0};
  TIM_MasterConfigTypeDef sMasterConfig = {0};

  htim2.Instance = TIM2;
  htim2.Init.Prescaler = 0;
  htim2.Init.CounterMode = TIM_COUNTERMODE_UP;
  htim2.Init.Period = 4294967295;
  htim2.Init.ClockDivision = TIM_CLOCKDIVISION_DIV1;
  htim2.Init.AutoReloadPreload = TIM_AUTORELOAD_PRELOAD_DISABLE;
  if (HAL_TIM_Base_Init(&htim2) != HAL_OK)
  {
    Error_Handler();
  }
  sClockSourceConfig.ClockSource = TIM_CLOCKSOURCE_INTERNAL;
  if (HAL_TIM_ConfigClockSource(&htim2, &sClockSourceConfig) != HAL_OK)
  {
    Error_Handler();
  }
  sMasterConfig.MasterOutputTrigger = TIM_TRGO_RESET;
  sMasterConfig.MasterSlaveMode = TIM_MASTERSLAVEMODE_DISABLE;
  if (HAL_TIMEx_MasterConfigSynchronization(&htim2, &sMasterConfig) != HAL_OK)
  {
    Error_Handler();
  }

}

static void MX_UART7_Init(void)
{

  huart7.Instance = UART7;
  huart7.Init.BaudRate = 230400;
  huart7.Init.WordLength = UART_WORDLENGTH_8B;
  huart7.Init.StopBits = UART_STOPBITS_1;
  huart7.Init.Parity = UART_PARITY_NONE;
  huart7.Init.Mode = UART_MODE_TX_RX;
  huart7.Init.HwFlowCtl = UART_HWCONTROL_NONE;
  huart7.Init.OverSampling = UART_OVERSAMPLING_16;
  huart7.Init.OneBitSampling = UART_ONE_BIT_SAMPLE_DISABLE;
  huart7.AdvancedInit.AdvFeatureInit = UART_ADVFEATURE_NO_INIT;
  if (HAL_UART_Init(&huart7) != HAL_OK)
  {
    Error_Handler();
  }
  /* USER CODE BEGIN UART7_Init 2 */
  HAL_UART_Receive_DMA (&hRs485, (uint8_t*)RS485_UART_RxBuffer, RS485_BUFFER_SIZE);
  /* USER CODE END UART7_Init 2 */

}

static void MX_USART1_UART_Init(void)
{

  huart1.Instance = USART1;
  huart1.Init.BaudRate = 921600;
  huart1.Init.WordLength = UART_WORDLENGTH_8B;
  huart1.Init.StopBits = UART_STOPBITS_1;
  huart1.Init.Parity = UART_PARITY_NONE;
  huart1.Init.Mode = UART_MODE_TX_RX;
  huart1.Init.HwFlowCtl = UART_HWCONTROL_NONE;
  huart1.Init.OverSampling = UART_OVERSAMPLING_16;
  huart1.Init.OneBitSampling = UART_ONE_BIT_SAMPLE_DISABLE;
  huart1.AdvancedInit.AdvFeatureInit = UART_ADVFEATURE_NO_INIT;
  if (HAL_UART_Init(&huart1) != HAL_OK)
  {
    Error_Handler();
  }
  /* USER CODE BEGIN USART1_Init 2 */
  HAL_UART_Receive_DMA (&husb, (uint8_t*)USB_UART_RxBuffer, RS485_BUFFER_SIZE);
  /* USER CODE END USART1_Init 2 */

}

static void MX_USART2_UART_Init(void)
{

  huart2.Instance = USART2;
  huart2.Init.BaudRate = 115200;
  huart2.Init.WordLength = UART_WORDLENGTH_8B;
  huart2.Init.StopBits = UART_STOPBITS_1;
  huart2.Init.Parity = UART_PARITY_NONE;
  huart2.Init.Mode = UART_MODE_TX_RX;
  huart2.Init.HwFlowCtl = UART_HWCONTROL_NONE;
  huart2.Init.OverSampling = UART_OVERSAMPLING_16;
  huart2.Init.OneBitSampling = UART_ONE_BIT_SAMPLE_DISABLE;
  huart2.AdvancedInit.AdvFeatureInit = UART_ADVFEATURE_NO_INIT;
  if (HAL_UART_Init(&huart2) != HAL_OK)
  {
    Error_Handler();
  }

}

static void MX_DMA_Init(void)
{

  /* DMA controller clock enable */
  __HAL_RCC_DMA2_CLK_ENABLE();
  __HAL_RCC_DMA1_CLK_ENABLE();

  /* DMA interrupt init */
  /* DMA1_Stream3_IRQn interrupt configuration */
  HAL_NVIC_SetPriority(DMA1_Stream3_IRQn, 5, 0);
  HAL_NVIC_EnableIRQ(DMA1_Stream3_IRQn);
  /* DMA2_Stream2_IRQn interrupt configuration */
  HAL_NVIC_SetPriority(DMA2_Stream2_IRQn, 5, 0);
  HAL_NVIC_EnableIRQ(DMA2_Stream2_IRQn);

}

/* FMC initialization function */
static void MX_FMC_Init(void)
{

  FMC_SDRAM_TimingTypeDef SdramTiming = {0};

  /** Perform the SDRAM1 memory initialization sequence
  */
  hsdram1.Instance = FMC_SDRAM_DEVICE;
  /* hsdram1.Init */
  hsdram1.Init.SDBank = FMC_SDRAM_BANK2;
  hsdram1.Init.ColumnBitsNumber = FMC_SDRAM_COLUMN_BITS_NUM_8;
  hsdram1.Init.RowBitsNumber = FMC_SDRAM_ROW_BITS_NUM_12;
  hsdram1.Init.MemoryDataWidth = FMC_SDRAM_MEM_BUS_WIDTH_16;
  hsdram1.Init.InternalBankNumber = FMC_SDRAM_INTERN_BANKS_NUM_4;
  hsdram1.Init.CASLatency = FMC_SDRAM_CAS_LATENCY_3;
  hsdram1.Init.WriteProtection = FMC_SDRAM_WRITE_PROTECTION_DISABLE;
  hsdram1.Init.SDClockPeriod = FMC_SDRAM_CLOCK_PERIOD_2;
  hsdram1.Init.ReadBurst = FMC_SDRAM_RBURST_ENABLE;
  hsdram1.Init.ReadPipeDelay = FMC_SDRAM_RPIPE_DELAY_0;
  /* SdramTiming */
  SdramTiming.LoadToActiveDelay = 2;
  SdramTiming.ExitSelfRefreshDelay = 7;
  SdramTiming.SelfRefreshTime = 4;
  SdramTiming.RowCycleDelay = 7;
  SdramTiming.WriteRecoveryTime = 3;
  SdramTiming.RPDelay = 2;
  SdramTiming.RCDDelay = 2;

  if (HAL_SDRAM_Init(&hsdram1, &SdramTiming) != HAL_OK)
  {
    Error_Handler( );
  }

  /* USER CODE BEGIN FMC_Init 2 */
  __IO uint32_t tmpmrd = 0;
  FMC_SDRAM_CommandTypeDef Command;

  /* Step 1: Configure a clock configuration enable command */
  Command.CommandMode            = FMC_SDRAM_CMD_CLK_ENABLE;
  Command.CommandTarget          = FMC_SDRAM_CMD_TARGET_BANK2;
  Command.AutoRefreshNumber      = 1;
  Command.ModeRegisterDefinition = 0;

  /* Send the command */
  HAL_SDRAM_SendCommand(&hsdram1, &Command, SDRAM_TIMEOUT);

  /* Step 2: Insert 100 us minimum delay */
  /* Inserted delay is equal to 1 ms due to systick time base unit (ms) */
  HAL_Delay(1);

  /* Step 3: Configure a PALL (precharge all) command */
  Command.CommandMode            = FMC_SDRAM_CMD_PALL;
  Command.CommandTarget          = FMC_SDRAM_CMD_TARGET_BANK2;
  Command.AutoRefreshNumber      = 1;
  Command.ModeRegisterDefinition = 0;

  /* Send the command */
  HAL_SDRAM_SendCommand(&hsdram1, &Command, SDRAM_TIMEOUT);

  /* Step 4: Configure an Auto Refresh command */
  Command.CommandMode            = FMC_SDRAM_CMD_AUTOREFRESH_MODE;
  Command.CommandTarget          = FMC_SDRAM_CMD_TARGET_BANK2;
  Command.AutoRefreshNumber      = 8;
  Command.ModeRegisterDefinition = 0;

  /* Send the command */
  HAL_SDRAM_SendCommand(&hsdram1, &Command, SDRAM_TIMEOUT);

  /* Step 5: Program the external memory mode register */
  tmpmrd = (uint32_t)SDRAM_MODEREG_BURST_LENGTH_1          |\
                     SDRAM_MODEREG_BURST_TYPE_SEQUENTIAL   |\
                     SDRAM_MODEREG_CAS_LATENCY_3           |\
                     SDRAM_MODEREG_OPERATING_MODE_STANDARD |\
                     SDRAM_MODEREG_WRITEBURST_MODE_SINGLE;

  Command.CommandMode            = FMC_SDRAM_CMD_LOAD_MODE;
  Command.CommandTarget          = FMC_SDRAM_CMD_TARGET_BANK2;
  Command.AutoRefreshNumber      = 1;
  Command.ModeRegisterDefinition = tmpmrd;

  /* Send the command */
  HAL_SDRAM_SendCommand(&hsdram1, &Command, SDRAM_TIMEOUT);

  /* Step 6: Set the refresh rate counter */
  /* Set the device refresh rate */
  HAL_SDRAM_ProgramRefreshRate(&hsdram1, SDRAM_REFRESH_COUNT);

  //Deactivate speculative/cache access to first FMC Bank to save FMC bandwidth
  FMC_Bank1->BTCR[0] = 0x000030D2;
  /* USER CODE END FMC_Init 2 */
}

static void MX_GPIO_Init(void)
{
  GPIO_InitTypeDef GPIO_InitStruct = {0};

  /* GPIO Ports Clock Enable */
  __HAL_RCC_GPIOE_CLK_ENABLE();
  __HAL_RCC_GPIOI_CLK_ENABLE();
  __HAL_RCC_GPIOC_CLK_ENABLE();
  __HAL_RCC_GPIOF_CLK_ENABLE();
  __HAL_RCC_GPIOH_CLK_ENABLE();
  __HAL_RCC_GPIOA_CLK_ENABLE();
  __HAL_RCC_GPIOB_CLK_ENABLE();
  __HAL_RCC_GPIOG_CLK_ENABLE();
  __HAL_RCC_GPIOD_CLK_ENABLE();

  /*Configure GPIO pin Output Level */
  HAL_GPIO_WritePin(DO_EN_GPIO_Port, DO_EN_Pin, GPIO_PIN_RESET);

  /*Configure GPIO pin Output Level */
  HAL_GPIO_WritePin(RS_485_DIR_GPIO_Port, RS_485_DIR_Pin, GPIO_PIN_RESET);

  /*Configure GPIO pin Output Level */
  HAL_GPIO_WritePin(AIN_CS_GPIO_Port, AIN_CS_Pin, GPIO_PIN_SET);

  /*Configure GPIO pin Output Level */
  HAL_GPIO_WritePin(GPIOC, LIVE_LED_Pin|DIO_LD_Pin|DISP_EN_Pin, GPIO_PIN_RESET);

  /*Configure GPIO pin Output Level */
  HAL_GPIO_WritePin(TS_RST_GPIO_Port, TS_RST_Pin, GPIO_PIN_RESET);

  /*Configure GPIO pin Output Level */
  HAL_GPIO_WritePin(GPIOB, DIO_WR_Pin|SPI2_CLK_Pin|SPI2_MOSI_Pin, GPIO_PIN_RESET);

  /*Configure GPIO pin Output Level */
  HAL_GPIO_WritePin(GPIOG, FLS_CS_Pin|DIO_CS_Pin, GPIO_PIN_SET);

  /*Configure GPIO pin : DO_EN_Pin */
  GPIO_InitStruct.Pin = DO_EN_Pin;
  GPIO_InitStruct.Mode = GPIO_MODE_OUTPUT_PP;
  GPIO_InitStruct.Pull = GPIO_NOPULL;
  GPIO_InitStruct.Speed = GPIO_SPEED_FREQ_LOW;
  HAL_GPIO_Init(DO_EN_GPIO_Port, &GPIO_InitStruct);

  /*Configure GPIO pin : RS_485_DIR_Pin */
  GPIO_InitStruct.Pin = RS_485_DIR_Pin;
  GPIO_InitStruct.Mode = GPIO_MODE_OUTPUT_PP;
  GPIO_InitStruct.Pull = GPIO_NOPULL;
  GPIO_InitStruct.Speed = GPIO_SPEED_FREQ_LOW;
  HAL_GPIO_Init(RS_485_DIR_GPIO_Port, &GPIO_InitStruct);

  /*Configure GPIO pin : AIN_CS_Pin */
  GPIO_InitStruct.Pin = AIN_CS_Pin;
  GPIO_InitStruct.Mode = GPIO_MODE_OUTPUT_PP;
  GPIO_InitStruct.Pull = GPIO_PULLUP;
  GPIO_InitStruct.Speed = GPIO_SPEED_FREQ_LOW;
  HAL_GPIO_Init(AIN_CS_GPIO_Port, &GPIO_InitStruct);

  /*Configure GPIO pins : LIVE_LED_Pin DIO_LD_Pin */
  GPIO_InitStruct.Pin = LIVE_LED_Pin|DIO_LD_Pin;
  GPIO_InitStruct.Mode = GPIO_MODE_OUTPUT_PP;
  GPIO_InitStruct.Pull = GPIO_NOPULL;
  GPIO_InitStruct.Speed = GPIO_SPEED_FREQ_LOW;
  HAL_GPIO_Init(GPIOC, &GPIO_InitStruct);

  /*Configure GPIO pin : TS_RST_Pin */
  GPIO_InitStruct.Pin = TS_RST_Pin;
  GPIO_InitStruct.Mode = GPIO_MODE_OUTPUT_PP;
  GPIO_InitStruct.Pull = GPIO_NOPULL;
  GPIO_InitStruct.Speed = GPIO_SPEED_FREQ_LOW;
  HAL_GPIO_Init(TS_RST_GPIO_Port, &GPIO_InitStruct);

  /*Configure GPIO pin : TS_INT_Pin */
  GPIO_InitStruct.Pin = TS_INT_Pin;
  GPIO_InitStruct.Mode = GPIO_MODE_IT_FALLING;
  GPIO_InitStruct.Pull = GPIO_PULLUP;
  HAL_GPIO_Init(TS_INT_GPIO_Port, &GPIO_InitStruct);

  /*Configure GPIO pins : DIO_WR_Pin SPI2_CLK_Pin SPI2_MOSI_Pin */
  GPIO_InitStruct.Pin = DIO_WR_Pin|SPI2_CLK_Pin|SPI2_MOSI_Pin;
  GPIO_InitStruct.Mode = GPIO_MODE_OUTPUT_PP;
  GPIO_InitStruct.Pull = GPIO_NOPULL;
  GPIO_InitStruct.Speed = GPIO_SPEED_FREQ_LOW;
  HAL_GPIO_Init(GPIOB, &GPIO_InitStruct);

  /*Configure GPIO pin : SPI2_MISO_Pin */
  GPIO_InitStruct.Pin = SPI2_MISO_Pin;
  GPIO_InitStruct.Mode = GPIO_MODE_INPUT;
  GPIO_InitStruct.Pull = GPIO_NOPULL;
  HAL_GPIO_Init(SPI2_MISO_GPIO_Port, &GPIO_InitStruct);

  /*Configure GPIO pins : FLS_CS_Pin DIO_CS_Pin */
  GPIO_InitStruct.Pin = FLS_CS_Pin|DIO_CS_Pin;
  GPIO_InitStruct.Mode = GPIO_MODE_OUTPUT_PP;
  GPIO_InitStruct.Pull = GPIO_PULLUP;
  GPIO_InitStruct.Speed = GPIO_SPEED_FREQ_LOW;
  HAL_GPIO_Init(GPIOG, &GPIO_InitStruct);

  /*Configure GPIO pin : DISP_EN_Pin */
  GPIO_InitStruct.Pin = DISP_EN_Pin;
  GPIO_InitStruct.Mode = GPIO_MODE_OUTPUT_PP;
  GPIO_InitStruct.Pull = GPIO_PULLDOWN;
  GPIO_InitStruct.Speed = GPIO_SPEED_FREQ_LOW;
  HAL_GPIO_Init(DISP_EN_GPIO_Port, &GPIO_InitStruct);

  /* EXTI interrupt init*/
  HAL_NVIC_SetPriority(EXTI15_10_IRQn, 5, 0);
  HAL_NVIC_EnableIRQ(EXTI15_10_IRQn);

}

/* USER CODE BEGIN 4 */

/* LEDs ---------------------------------------------------------------------*/
void LiveLedOn(void)
{
  HAL_GPIO_WritePin(LIVE_LED_GPIO_Port, LIVE_LED_Pin, GPIO_PIN_SET);
}

void LiveLedOff(void)
{
  HAL_GPIO_WritePin(LIVE_LED_GPIO_Port, LIVE_LED_Pin, GPIO_PIN_RESET);
}

/* Flash ---------------------------------------------------------------------*/
int Read (uint32_t address, uint32_t size, uint8_t* buffer)
{
  int i = 0;
  for (i=0; i < size;i++)
  {
    *(uint8_t*)buffer++ = *(uint8_t*)address;
    address ++;
  }
  return 1;
}

/* FreeRTOS ------------------------------------------------------------------*/
void configureTimerForRunTimeStats(void)
{
  HAL_TIM_Base_Start_IT(&htim2);
}

unsigned long getRunTimeCounterValue(void)
{
  return RTOSRunTimeStatTick;
}

/* Display--------------------------------------------------------------------*/
void SetDisplayOn()
{
  HAL_GPIO_WritePin(DISP_EN_GPIO_Port, DISP_EN_Pin, GPIO_PIN_SET);
}
void SetDisplayOff()
{
  HAL_GPIO_WritePin(DISP_EN_GPIO_Port, DISP_EN_Pin, GPIO_PIN_RESET);
}

uint8_t GetDisply(void)
{
  return HAL_GPIO_ReadPin(DISP_EN_GPIO_Port, DISP_EN_Pin) == GPIO_PIN_SET;
}

/* Usb------------------------------------------------------------------------*/
void UsbUartTx(char *str)
{
  strcat(str,"\n");
  HAL_UART_Transmit(&husb, (uint8_t*)str, strlen(str), 100);
}

void UsbParser(char *request)
{
  char response[USB_BUFFER_SIZE];
  char cmd[20];
  char arg1[10];

  if(strlen(USB_UART_RxBuffer) !=0)
  {
    memset(cmd,0x00, sizeof(cmd));
    memset(arg1,0x00, sizeof(arg1));

    sscanf(request, "%s", cmd);

    if(!strcmp(cmd, "*OPC?"))
    {
      strcpy(response, "*OPC");
    }
    else if(!strcmp(cmd, "OK?"))
    {
      strcpy(response, "OK");
    }
    else if(!strcmp(cmd, "*WHOIS?"))
    {
      strcpy(response, DEVICE_NAME);
    }
    else if(!strcmp(cmd, "*VER?"))
    {
      strcpy(response, DEVICE_FW);
    }
    else if(!strcmp(cmd, "*UID?"))
    {
      sprintf(response, "%4lX%4lX%4lX",HAL_GetUIDw0(), HAL_GetUIDw1(), HAL_GetUIDw2());
    }
    else if(!strcmp(cmd,"UPTIME?"))
    {
      sprintf(response, "%lld", Device.Gui.UpTimeSec);
    }
    else if(!strcmp(cmd, "DIS:LIG?"))
    {
      sprintf(response, "%d", Device.Backlight.LightPercent);
    }
    else if(!strcmp(cmd, "DIS?"))
    {
      sprintf(response, "%d",GetDisply()?1:0);
    }
    else if(!strcmp(cmd, "DIS:ON"))
    {
      SetDisplayOn();
      strcpy(response, "OK");
    }
    else if(!strcmp(cmd, "DIS:OFF"))
    {
      SetDisplayOff();
      strcpy(response, "OK");
    }
    else if(!strcmp(cmd, "DIG:INP:U16?"))
    {
      sprintf(response, "%04X",PeriphReadInputs());
    }
    else if(!strcmp(cmd, "DIG:OUT:U8?"))
    {
      strcpy(response, "!UNKNOWN");
    }
    else if(!strcmp(cmd, "DIG:OUT:SET:U8"))
    {
      sscanf(request, "%s %s", cmd, arg1);
      uint8_t value = strtol(arg1, NULL, 16);

      PeriphWriteOutputs(value);
      strcpy(response, "OK");
    }
    else if(!strcmp(cmd,"RST"))
    {
      strcpy(response, "OK");
      UsbUartTx(response);
      NVIC_SystemReset();
    }
    else
    {
      strcpy(response, "!UNKNOWN");
    }
    UsbUartTx(response);
  }
}

/* RTC -----------------------------------------------------------------------*/
uint8_t DeviceRtcSet(time_t dt)
{
#if rtc_test
  /*** Loopback for test ***/
  struct tm tm_out = {0};
  struct tm *tm_in = gmtime(&dt);

  tm_out.tm_year = tm_in->tm_year;
  tm_out.tm_mon = tm_in->tm_mon;
  tm_out.tm_mday = tm_in->tm_mday;

  tm_out.tm_hour = tm_in->tm_hour;
  tm_out.tm_min = tm_in->tm_min;
  tm_out.tm_sec = tm_in->tm_sec;

  Device.DateTime.PosixTime = mktime(&tm_out);
#endif

  struct tm *tm_info = gmtime(&dt);

  RTC_DateTypeDef date;
  date.Year = tm_info->tm_year - 100;
  date.Month = tm_info->tm_mon + 1;
  date.Date = tm_info->tm_mday;
  date.WeekDay = 0;
  if(HAL_RTC_SetDate(&hrtc, &date, RTC_FORMAT_BIN) != HAL_OK)
    return DEVICE_FAIL;

  RTC_TimeTypeDef time;
  time.Hours = tm_info->tm_hour;
  time.Minutes = tm_info->tm_min;
  time.Seconds = tm_info->tm_sec;
  time.DayLightSaving = RTC_DAYLIGHTSAVING_NONE;
  time.StoreOperation = RTC_STOREOPERATION_SET;

  if(HAL_RTC_SetTime(&hrtc, &time, RTC_FORMAT_BIN) != HAL_OK)
    return DEVICE_FAIL;

  return DEVICE_OK;
}

uint8_t DeviceRtcGet(time_t *dt)
{
  //Have to read time first!!!!!!!!!!!!!!!!!!!!!!!!!!!!!!!!!!!!!!!!!!!!!!!!!!!!!
  RTC_TimeTypeDef time;
  if(HAL_RTC_GetTime(&hrtc, &time, RTC_FORMAT_BIN) != HAL_OK)
    return DEVICE_FAIL;

  RTC_DateTypeDef date;
  if(HAL_RTC_GetDate(&hrtc, &date, RTC_FORMAT_BIN) != HAL_OK)
    return DEVICE_FAIL;

  struct tm tm_info;
  tm_info.tm_year = 2000 - 1900 + date.Year ;
  tm_info.tm_mon = date.Month - 1;
  tm_info.tm_mday = date.Date;
  tm_info.tm_hour = time.Hours;
  tm_info.tm_min = time.Minutes;
  tm_info.tm_sec = time.Seconds;
  if (time.DayLightSaving == RTC_DAYLIGHTSAVING_SUB1H)
    tm_info.tm_isdst = -1;
  else if (time.DayLightSaving == RTC_DAYLIGHTSAVING_ADD1H)
    tm_info.tm_isdst = 1;
  else
    tm_info.tm_isdst = 0;

  *dt = mktime(&tm_info);

  return DEVICE_OK;
}

uint8_t DeviceTimeUpdate()
{
  /*** Device Real Time Clock Update ***/
  if(DeviceRtcGet(&Device.DateTime.PosixTime) != DEVICE_OK)
    return DEVICE_FAIL;

  struct tm *tm_info  = localtime(&Device.DateTime.PosixTime);
  Device.DateTime.tmDateTime.tm_year = tm_info->tm_year;
  Device.DateTime.tmDateTime.tm_mon = tm_info->tm_mon;
  Device.DateTime.tmDateTime.tm_mday = tm_info->tm_mday;
  Device.DateTime.tmDateTime.tm_hour = tm_info->tm_hour;
  Device.DateTime.tmDateTime.tm_min = tm_info->tm_min;
  Device.DateTime.tmDateTime.tm_year = tm_info->tm_year;
  Device.DateTime.tmDateTime.tm_sec = tm_info->tm_sec;
  Device.DateTime.tmDateTime.tm_isdst = tm_info->tm_isdst;

  strftime(Device.DateTime.Now, DEVICE_DT_STR_SIZE, "%Y-%m-%d %H:%M:%S", tm_info );

  /*** Display Backlight Auto Off Timer ***/
  if(Device.Backlight.OffTimerSec != 0)
  {
    if(Device.Backlight.TimestampToOff == Device.DateTime.PosixTime)
    {
      BacklightEn(0);
      Device.Backlight.TouchInterrupt = 0;
    }
    if(Device.Backlight.TimestampToOff > Device.DateTime.PosixTime)
      Device.Backlight.RemainingTimeToOff = Device.Backlight.TimestampToOff - Device.DateTime.PosixTime;
  }
  else
  {
    Device.Backlight.RemainingTimeToOff = 0;
    Device.Backlight.TouchInterrupt = 0;
  }
  return DEVICE_OK;
}

void DeviceBacklightOffTimerReset(void)
{
  Device.Backlight.TimestampToOff = Device.Backlight.OffTimerSec + Device.DateTime.PosixTime;
  BacklightEn(1);
}

void HAL_GPIO_EXTI_Callback(uint16_t GPIO_Pin)
{
  if(Device.Backlight.OffTimerSec)
  {
    Device.Backlight.TouchInterrupt ++;
    DeviceBacklightOffTimerReset();
  }
}

/* RS485----------------------------------------------------------------------*/
void RS485DirTx(void)
{
  HAL_GPIO_WritePin(RS_485_DIR_GPIO_Port, RS_485_DIR_Pin, GPIO_PIN_SET);
}

void RS485DirRx(void)
{
  HAL_GPIO_WritePin(RS_485_DIR_GPIO_Port, RS_485_DIR_Pin, GPIO_PIN_RESET);
}

void RS485UartTx(char *str)
{
  RS485DirTx();
  HAL_Delay(RS485_TX_HOLD_MS);
  strcat(str,"\n");
  HAL_UART_Transmit(&hRs485, (uint8_t*)str, strlen(str), 100);
  RS485DirRx();
}

void RS485Parser(char *response)
{
  unsigned int addr = 0;
  char cmd[RS485_CMD_LENGTH];
  char arg1[RS485_ARG1_LENGTH];
  char arg2[RS485_ARG2_LENGTH];

  if(strlen(response) !=0)
  {
    memset(cmd,0x00, RS485_CMD_LENGTH);
    memset(arg1,0x00, RS485_ARG1_LENGTH);
    memset(arg2,0x00, RS485_ARG2_LENGTH);

    Device.Diag.RS485ResponseCnt++;
    sscanf(response, "#%x %s %s", &addr, cmd, arg1);
    if(addr == KRN_HOST_RX_ADDR )
    {
      if(!strcmp(cmd, "OK"))
      {
        Device.Karuna.OkCnt++;
      }
      else if(!strcmp(cmd, "FW"))
      {
         uint8_t i = strlen(arg1);
         if(i<DEVICE_FW_SIZE && i!=0)
           strcpy(Device.Karuna.FW, arg1);
         else
           strcpy(Device.Karuna.FW, "?");
      }
      else if(!strcmp(cmd, "UID"))
      {
        uint8_t i = strlen(arg1);
        if(i<DEVICE_UID_SIZE && i!=0)
          strcpy(Device.Karuna.UID, arg1);
        else
          strcpy(Device.Karuna.UID, "?");
      }
      else if(!strcmp(cmd, "PCB"))
      {
        uint8_t i = strlen(arg1);
        if(i<DEVICE_PCB_SIZE && i!=0)
          strcpy(Device.Karuna.PCB, arg1);
        else
          strcpy(Device.Karuna.PCB, "?");
      }
      else if(!strcmp(cmd,"UPTIME"))
      {
        Device.Karuna.UpTimeSec = strtol(arg1, NULL, 16);
      }
      else if(!strcmp(cmd, "DI"))
      {
        Device.Karuna.DI = strtol(arg1, NULL, 16);
      }
      else if(!strcmp(cmd, "DO"))
      {
        Device.Karuna.DO = strtol(arg1, NULL, 16);
      }
      else if(!strcmp(cmd, "UE"))
      {
        Device.Karuna.UartErrorCnt = strtol(arg1, NULL, 16);
      }
      else
      {
        Device.Karuna.UnknownCnt++;
      }
    }

    if(addr == DAS_HOST_RX_ADDR)
    {
      if(!strcmp(cmd, "OK"))
      {
        Device.DasClock.OkCnt++;
      }

      if(!strcmp(cmd, "FW"))
      {
        uint8_t i = strlen(arg1);
        if(i<DEVICE_FW_SIZE && i!=0)
          strcpy(Device.DasClock.FW, arg1);
        else
          strcpy(Device.DasClock.UID, "?");
      }
      else if(!strcmp(cmd, "UID"))
      {
        uint8_t i = strlen(arg1);
        if(i<DEVICE_UID_SIZE && i!=0)
          strcpy(Device.DasClock.UID, arg1);
        else
          strcpy(Device.DasClock.UID, "?");
      }
      else if(!strcmp(cmd, "PCB"))
      {
        uint8_t i = strlen(arg1);
        if(i<DEVICE_PCB_SIZE && i!=0)
          strcpy(Device.DasClock.PCB, arg1);
        else
          strcpy(Device.DasClock.PCB, "?");
      }
      else if(!strcmp(cmd,"UPTIME"))
      {
         Device.DasClock.UpTimeSec = strtol(arg1, NULL, 16);
      }
      else if(!strcmp(cmd, "DI"))
      {
        Device.DasClock.DI = strtol(arg1, NULL, 16);
      }
      else if(!strcmp(cmd, "DO"))
      {
        Device.DasClock.DO = strtol(arg1, NULL, 16);
      }
      else if(!strcmp(cmd, "UE"))
      {
        Device.DasClock.UartErrorCnt = strtol(arg1, NULL, 16);
      }
      if(!strcmp(cmd, "AI"))
      {
        sscanf(response, "#%x %s %s %s", &addr, cmd, arg1, arg2);
        uint8_t ch = strtol(arg1, NULL, 10);
        double value = atof(arg2);
        if(ch < DAS_AI_CHANNELS)
         Device.DasClock.AI[ch] = value;
      }
      else
      {
        Device.DasClock.UnknownCnt++;
      }
    }
  }
}

/* USER CODE END 4 */

void StartDefaultTask(void *argument)
{
  /* USER CODE BEGIN 5 */

  LogWriteLine("Start Default Task");

  MX_TouchGFX_Process();
  /* Infinite loop */
  for(;;)
  {
    osDelay(100);
  }
  /* USER CODE END 5 */
}

void UsbRxTask(void *argument)
{
  /* USER CODE BEGIN UsbRxTask */
  /* Infinite loop */
  static uint32_t timestamp;
  static uint8_t startFlag;
  for(;;)
  {
    if(strlen(USB_UART_RxBuffer)!=0)
    {
      if(!startFlag)
      {
        timestamp = HAL_GetTick();
        startFlag = 1;
      }
      for(uint8_t i=0; i < USB_BUFFER_SIZE; i++)
      {
        if(USB_UART_RxBuffer[i]=='\n')
        {
          USB_UART_RxBuffer[i] = 0;
          startFlag = 0;
          HAL_UART_DMAStop(&husb);
          UsbParser(USB_UART_RxBuffer);
          memset(USB_UART_RxBuffer, 0x00, USB_BUFFER_SIZE);
          HAL_UART_Receive_DMA(&husb, (uint8_t*) USB_UART_RxBuffer, USB_BUFFER_SIZE);
          break;
        }
      }
      if(startFlag)
      {
        if(HAL_GetTick() - timestamp > 500)
        {
          if(__HAL_UART_GET_FLAG(&husb, UART_FLAG_ORE))
            __HAL_UART_CLEAR_FLAG(&husb,UART_CLEAR_OREF);
          if(__HAL_UART_GET_FLAG(&husb, USART_ISR_NE))
            __HAL_UART_CLEAR_FLAG(&husb,USART_ISR_NE);
          if(__HAL_UART_GET_FLAG(&husb, USART_ISR_FE))
            __HAL_UART_CLEAR_FLAG(&husb,USART_ISR_FE);
          startFlag = 0;
          HAL_UART_DMAStop(&husb);
          memset(USB_UART_RxBuffer, 0x00, USB_BUFFER_SIZE);
          HAL_UART_Receive_DMA(&husb, (uint8_t*) USB_UART_RxBuffer, USB_BUFFER_SIZE);
          Device.Diag.UsbUartErrorCnt ++;
        }
      }
    }
    osDelay(10);
  }
  /* USER CODE END UsbRxTask */
}

void LiveLedOsTask(void *argument)
{
  /* USER CODE BEGIN LiveLedOsTask */
  /* Infinite loop */
  for(;;)
  {
    uint32_t timestamp = 0;
    uint8_t flag = 0;

    osDelay(1000);
    BacklightEn(1);
    for(;;)
    {
      if(HAL_GetTick() - timestamp > 500)
      {
        timestamp = HAL_GetTick();
        if(flag)
        {
          flag = 0;
          LiveLedOn();
          DeviceTimeUpdate();
        }
        else
        {
          flag = 1;
          LiveLedOff();
          Device.Gui.UpTimeSec++;
        }
      }
      osDelay(10);
    }
  }
  /* USER CODE END LiveLedOsTask */
}

void RS485RxTask(void *argument)
{
  /* USER CODE BEGIN RS485RxTask */
  /* Infinite loop */
  static uint32_t timestamp;
  static uint8_t startFlag;
  for(;;)
  {
    if(strlen(RS485_UART_RxBuffer)!=0)
    {
      if(!startFlag)
      {
        timestamp = HAL_GetTick();
        startFlag = 1;
      }
      for(uint8_t i=0; i < RS485_BUFFER_SIZE; i++)
      {
        if(RS485_UART_RxBuffer[i]=='\n')
        {
          RS485_UART_RxBuffer[i] = 0;
          startFlag = 0;
          HAL_UART_DMAStop(&hRs485);
          RS485Parser(RS485_UART_RxBuffer);
          memset(RS485_UART_RxBuffer, 0x00, RS485_BUFFER_SIZE);
          HAL_UART_Receive_DMA(&hRs485, (uint8_t*) RS485_UART_RxBuffer, RS485_BUFFER_SIZE);
          break;
        }
      }
      if(startFlag)
      {
        if(HAL_GetTick() - timestamp > 500)
        {
          if(__HAL_UART_GET_FLAG(&hRs485, UART_FLAG_ORE))
            __HAL_UART_CLEAR_FLAG(&hRs485,UART_CLEAR_OREF);
          if(__HAL_UART_GET_FLAG(&hRs485, USART_ISR_NE))
            __HAL_UART_CLEAR_FLAG(&hRs485,USART_ISR_NE);
          if(__HAL_UART_GET_FLAG(&hRs485, USART_ISR_FE))
            __HAL_UART_CLEAR_FLAG(&hRs485,USART_ISR_FE);
          startFlag = 0;
          HAL_UART_DMAStop(&hRs485);
          memset(RS485_UART_RxBuffer, 0x00, RS485_BUFFER_SIZE);
          HAL_UART_Receive_DMA(&hRs485, (uint8_t*) RS485_UART_RxBuffer, RS485_BUFFER_SIZE);
          Device.Diag.RS485UartErrorCnt ++;
        }
      }
    }
    osDelay(10);
  }
  /* USER CODE END RS485RxTask */
}

void RS485TxTask(void *argument)
{
  /* USER CODE BEGIN RS485TxTask */
  /* Infinite loop */
  static char buffer[RS485_BUFFER_SIZE];
  memset(buffer, 0xCC, RS485_BUFFER_SIZE);

  for(;;)
  {
    for(uint8_t i=0; i< sizeof(RS485TxCollection)/sizeof(RS485TxItem_t); i++)
    {
      if(HAL_GetTick() - RS485TxCollection[i].Timesamp > RS485TxCollection[i].PeriodTime )
      {
        RS485TxCollection[i].Timesamp = HAL_GetTick();
        switch(RS485TxCollection[i].Type)
        {
          case TX_ITEM_NO_ARG:
          {
            sprintf(buffer, RS485TxCollection[i].Command, RS485TxCollection[i].HostAddr);
            break;
          }
          case TX_ITEM_INT_ARG:
          {
            sprintf(buffer, RS485TxCollection[i].Command, RS485TxCollection[i].HostAddr, *((uint32_t*)RS485TxCollection[i].Arg1));
            break;
          }
        }
        RS485UartTx(buffer);
      }
      osDelay(10);
    }
  }
  /* USER CODE END RS485TxTask */
}

void PeriTask(void *argument)
{
  /* USER CODE BEGIN PeriTask */
  /* Infinite loop */
  for(;;)
  {
    Device.Gui.DI = PeriphReadInputs();
    PeriphWriteOutputs(Device.Gui.DO);

    Device.Gui.Temps[AI_CH0] = PeriphReadTemp(AI_CH0);
    Device.Gui.Temps[AI_CH1] = PeriphReadTemp(AI_CH1);
    Device.Gui.Temps[AI_CH2] = PeriphReadTemp(AI_CH2);
    Device.Gui.Temps[AI_CH3] = PeriphReadTemp(AI_CH3);
    osDelay(100);
  }
  /* USER CODE END PeriTask */
}

void HAL_TIM_PeriodElapsedCallback(TIM_HandleTypeDef *htim)
{
  if (htim->Instance == TIM6) {
    HAL_IncTick();
  }
}

void Error_Handler(void)
{
}

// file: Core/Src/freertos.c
/* USER CODE BEGIN Header */
/**
  ******************************************************************************
  * File Name          : freertos.c
  * Description        : Code for freertos applications
  ******************************************************************************
  * @attention
  *
  * <h2><center>&copy; Copyright (c) 2020 STMicroelectronics.
  * All rights reserved.</center></h2>
  *
  * This software component is licensed by ST under Ultimate Liberty license
  * SLA0044, the "License"; You may not use this file except in compliance with
  * the License. You may obtain a copy of the License at:
  *                             www.st.com/SLA0044
  *
  ******************************************************************************
  */
/* USER CODE END Header */

#include "FreeRTOS.h"
#include "task.h"
#include "main.h"

/* USER CODE BEGIN FunctionPrototypes */
extern portBASE_TYPE IdleTaskHook(void* p);
/* USER CODE END FunctionPrototypes */

/* Hook prototypes */
void vApplicationIdleHook(void);

/* USER CODE BEGIN 2 */
void vApplicationIdleHook( void )
{
   /* vApplicationIdleHook() will only be called if configUSE_IDLE_HOOK is set
   to 1 in FreeRTOSConfig.h. It will be called on each iteration of the idle
   task. It is essential that code added to this hook function never attempts
   to block in any way (for example, call xQueueReceive() with a block time
   specified, or call vTaskDelay()). If the application makes use of the
   vTaskDelete() API function (as this demo application does) then it is also
   important that vApplicationIdleHook() is permitted to return to its calling
   function, because it is the responsibility of the idle task to clean up
   memory allocated by the kernel to any task that has since been deleted. */

   vTaskSetApplicationTaskTag(NULL, IdleTaskHook);
}
/* USER CODE END 2 */
